[part 1 of 9: packages /SwComponent/AdaptiveApplication to /DataType/Implementation/CPP]
AUTOSAR XML (schema 00049)
package /SwComponent/AdaptiveApplication
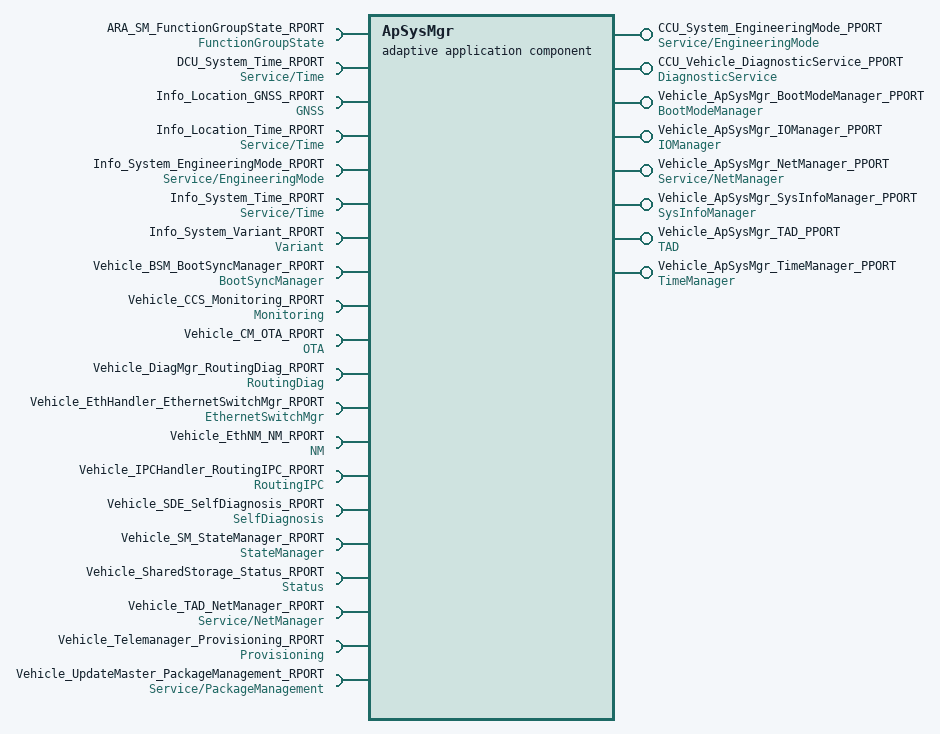
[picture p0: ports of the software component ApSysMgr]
  adaptive application sw component type ApSysMgr
    require port ARA_SM_FunctionGroupState_RPORT: required-interface=FunctionGroupState
    provide port CCU_System_EngineeringMode_PPORT: provided-interface=Service/EngineeringMode
    provide port CCU_Vehicle_DiagnosticService_PPORT: provided-interface=DiagnosticService
    6 x require port:
      DCU_System_Time_RPORT: required-interface=Service/Time
      Info_Location_GNSS_RPORT: required-interface=GNSS
      Info_Location_Time_RPORT: required-interface=Service/Time
      Info_System_EngineeringMode_RPORT: required-interface=Service/EngineeringMode
      Info_System_Time_RPORT: required-interface=Service/Time
      Info_System_Variant_RPORT: required-interface=Variant
    6 x provide port:
      Vehicle_ApSysMgr_BootModeManager_PPORT: provided-interface=BootModeManager
      Vehicle_ApSysMgr_IOManager_PPORT: provided-interface=IOManager
      Vehicle_ApSysMgr_NetManager_PPORT: provided-interface=Service/NetManager
      Vehicle_ApSysMgr_SysInfoManager_PPORT: provided-interface=SysInfoManager
      Vehicle_ApSysMgr_TAD_PPORT: provided-interface=TAD
      Vehicle_ApSysMgr_TimeManager_PPORT: provided-interface=TimeManager
    13 x require port:
      Vehicle_BSM_BootSyncManager_RPORT: required-interface=BootSyncManager
      Vehicle_CCS_Monitoring_RPORT: required-interface=Monitoring
      Vehicle_CM_OTA_RPORT: required-interface=OTA
      Vehicle_DiagMgr_RoutingDiag_RPORT: required-interface=RoutingDiag
      Vehicle_EthHandler_EthernetSwitchMgr_RPORT: required-interface=EthernetSwitchMgr
      Vehicle_EthNM_NM_RPORT: required-interface=NM
      Vehicle_IPCHandler_RoutingIPC_RPORT: required-interface=RoutingIPC
      Vehicle_SDE_SelfDiagnosis_RPORT: required-interface=SelfDiagnosis
      Vehicle_SM_StateManager_RPORT: required-interface=StateManager
      Vehicle_SharedStorage_Status_RPORT: required-interface=Status
      Vehicle_TAD_NetManager_RPORT: required-interface=Service/NetManager
      Vehicle_Telemanager_Provisioning_RPORT: required-interface=Provisioning
      Vehicle_UpdateMaster_PackageManagement_RPORT: required-interface=Service/PackageManagement
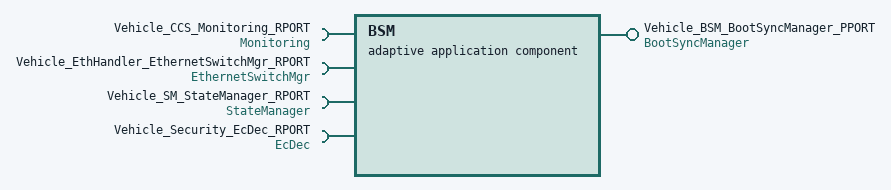
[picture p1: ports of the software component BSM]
  adaptive application sw component type BSM
    provide port Vehicle_BSM_BootSyncManager_PPORT: provided-interface=BootSyncManager
    4 x require port:
      Vehicle_CCS_Monitoring_RPORT: required-interface=Monitoring
      Vehicle_EthHandler_EthernetSwitchMgr_RPORT: required-interface=EthernetSwitchMgr
      Vehicle_SM_StateManager_RPORT: required-interface=StateManager
      Vehicle_Security_EcDec_RPORT: required-interface=EcDec
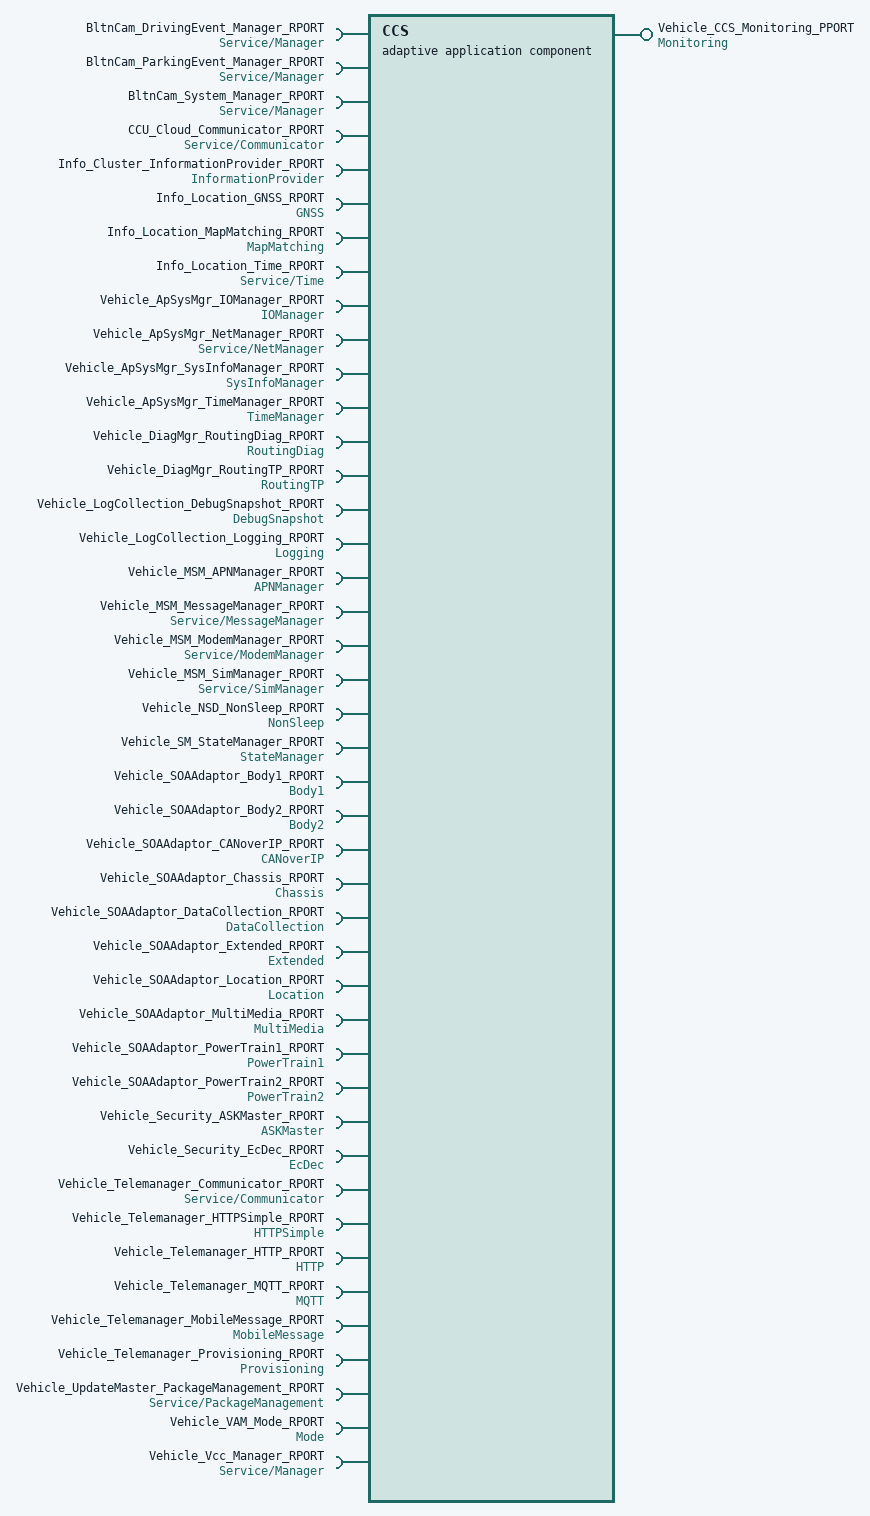
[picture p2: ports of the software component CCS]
  adaptive application sw component type CCS
    12 x require port:
      BltnCam_DrivingEvent_Manager_RPORT: required-interface=Service/Manager
      BltnCam_ParkingEvent_Manager_RPORT: required-interface=Service/Manager
      BltnCam_System_Manager_RPORT: required-interface=Service/Manager
      CCU_Cloud_Communicator_RPORT: required-interface=Service/Communicator
      Info_Cluster_InformationProvider_RPORT: required-interface=InformationProvider
      Info_Location_GNSS_RPORT: required-interface=GNSS
      Info_Location_MapMatching_RPORT: required-interface=MapMatching
      Info_Location_Time_RPORT: required-interface=Service/Time
      Vehicle_ApSysMgr_IOManager_RPORT: required-interface=IOManager
      Vehicle_ApSysMgr_NetManager_RPORT: required-interface=Service/NetManager
      Vehicle_ApSysMgr_SysInfoManager_RPORT: required-interface=SysInfoManager
      Vehicle_ApSysMgr_TimeManager_RPORT: required-interface=TimeManager
    provide port Vehicle_CCS_Monitoring_PPORT: provided-interface=Monitoring
    31 x require port:
      Vehicle_DiagMgr_RoutingDiag_RPORT: required-interface=RoutingDiag
      Vehicle_DiagMgr_RoutingTP_RPORT: required-interface=RoutingTP
      Vehicle_LogCollection_DebugSnapshot_RPORT: required-interface=DebugSnapshot
      Vehicle_LogCollection_Logging_RPORT: required-interface=Logging
      Vehicle_MSM_APNManager_RPORT: required-interface=APNManager
      Vehicle_MSM_MessageManager_RPORT: required-interface=Service/MessageManager
      Vehicle_MSM_ModemManager_RPORT: required-interface=Service/ModemManager
      Vehicle_MSM_SimManager_RPORT: required-interface=Service/SimManager
      Vehicle_NSD_NonSleep_RPORT: required-interface=NonSleep
      Vehicle_SM_StateManager_RPORT: required-interface=StateManager
      Vehicle_SOAAdaptor_Body1_RPORT: required-interface=Body1
      Vehicle_SOAAdaptor_Body2_RPORT: required-interface=Body2
      Vehicle_SOAAdaptor_CANoverIP_RPORT: required-interface=CANoverIP
      Vehicle_SOAAdaptor_Chassis_RPORT: required-interface=Chassis
      Vehicle_SOAAdaptor_DataCollection_RPORT: required-interface=DataCollection
      Vehicle_SOAAdaptor_Extended_RPORT: required-interface=Extended
      Vehicle_SOAAdaptor_Location_RPORT: required-interface=Location
      Vehicle_SOAAdaptor_MultiMedia_RPORT: required-interface=MultiMedia
      Vehicle_SOAAdaptor_PowerTrain1_RPORT: required-interface=PowerTrain1
      Vehicle_SOAAdaptor_PowerTrain2_RPORT: required-interface=PowerTrain2
      Vehicle_Security_ASKMaster_RPORT: required-interface=ASKMaster
      Vehicle_Security_EcDec_RPORT: required-interface=EcDec
      Vehicle_Telemanager_Communicator_RPORT: required-interface=Service/Communicator
      Vehicle_Telemanager_HTTPSimple_RPORT: required-interface=HTTPSimple
      Vehicle_Telemanager_HTTP_RPORT: required-interface=HTTP
      Vehicle_Telemanager_MQTT_RPORT: required-interface=MQTT
      Vehicle_Telemanager_MobileMessage_RPORT: required-interface=MobileMessage
      Vehicle_Telemanager_Provisioning_RPORT: required-interface=Provisioning
      Vehicle_UpdateMaster_PackageManagement_RPORT: required-interface=Service/PackageManagement
      Vehicle_VAM_Mode_RPORT: required-interface=Mode
      Vehicle_Vcc_Manager_RPORT: required-interface=Service/Manager
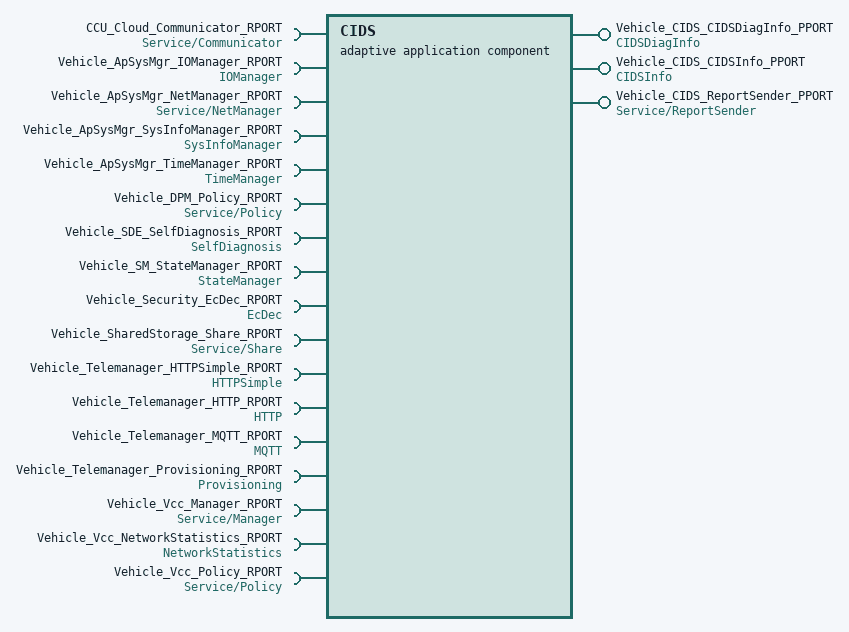
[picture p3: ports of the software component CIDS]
  adaptive application sw component type CIDS
    5 x require port:
      CCU_Cloud_Communicator_RPORT: required-interface=Service/Communicator
      Vehicle_ApSysMgr_IOManager_RPORT: required-interface=IOManager
      Vehicle_ApSysMgr_NetManager_RPORT: required-interface=Service/NetManager
      Vehicle_ApSysMgr_SysInfoManager_RPORT: required-interface=SysInfoManager
      Vehicle_ApSysMgr_TimeManager_RPORT: required-interface=TimeManager
    provide port Vehicle_CIDS_CIDSDiagInfo_PPORT: provided-interface=CIDSDiagInfo
    provide port Vehicle_CIDS_CIDSInfo_PPORT: provided-interface=CIDSInfo
    provide port Vehicle_CIDS_ReportSender_PPORT: provided-interface=Service/ReportSender
    12 x require port:
      Vehicle_DPM_Policy_RPORT: required-interface=Service/Policy
      Vehicle_SDE_SelfDiagnosis_RPORT: required-interface=SelfDiagnosis
      Vehicle_SM_StateManager_RPORT: required-interface=StateManager
      Vehicle_Security_EcDec_RPORT: required-interface=EcDec
      Vehicle_SharedStorage_Share_RPORT: required-interface=Service/Share
      Vehicle_Telemanager_HTTPSimple_RPORT: required-interface=HTTPSimple
      Vehicle_Telemanager_HTTP_RPORT: required-interface=HTTP
      Vehicle_Telemanager_MQTT_RPORT: required-interface=MQTT
      Vehicle_Telemanager_Provisioning_RPORT: required-interface=Provisioning
      Vehicle_Vcc_Manager_RPORT: required-interface=Service/Manager
      Vehicle_Vcc_NetworkStatistics_RPORT: required-interface=NetworkStatistics
      Vehicle_Vcc_Policy_RPORT: required-interface=Service/Policy
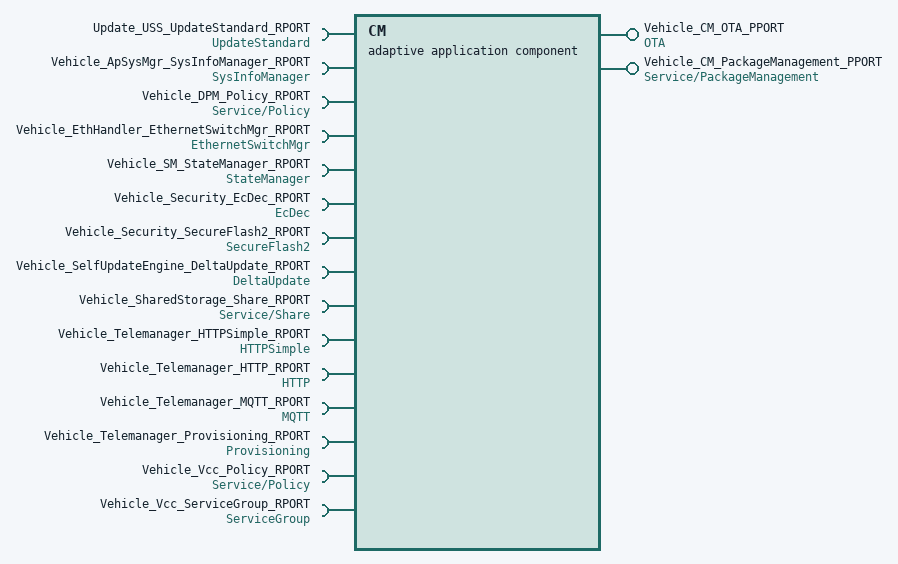
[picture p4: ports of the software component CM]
  adaptive application sw component type CM
    require port Update_USS_UpdateStandard_RPORT: required-interface=UpdateStandard
    require port Vehicle_ApSysMgr_SysInfoManager_RPORT: required-interface=SysInfoManager
    provide port Vehicle_CM_OTA_PPORT: provided-interface=OTA
    provide port Vehicle_CM_PackageManagement_PPORT: provided-interface=Service/PackageManagement
    13 x require port:
      Vehicle_DPM_Policy_RPORT: required-interface=Service/Policy
      Vehicle_EthHandler_EthernetSwitchMgr_RPORT: required-interface=EthernetSwitchMgr
      Vehicle_SM_StateManager_RPORT: required-interface=StateManager
      Vehicle_Security_EcDec_RPORT: required-interface=EcDec
      Vehicle_Security_SecureFlash2_RPORT: required-interface=SecureFlash2
      Vehicle_SelfUpdateEngine_DeltaUpdate_RPORT: required-interface=DeltaUpdate
      Vehicle_SharedStorage_Share_RPORT: required-interface=Service/Share
      Vehicle_Telemanager_HTTPSimple_RPORT: required-interface=HTTPSimple
      Vehicle_Telemanager_HTTP_RPORT: required-interface=HTTP
      Vehicle_Telemanager_MQTT_RPORT: required-interface=MQTT
      Vehicle_Telemanager_Provisioning_RPORT: required-interface=Provisioning
      Vehicle_Vcc_Policy_RPORT: required-interface=Service/Policy
      Vehicle_Vcc_ServiceGroup_RPORT: required-interface=ServiceGroup
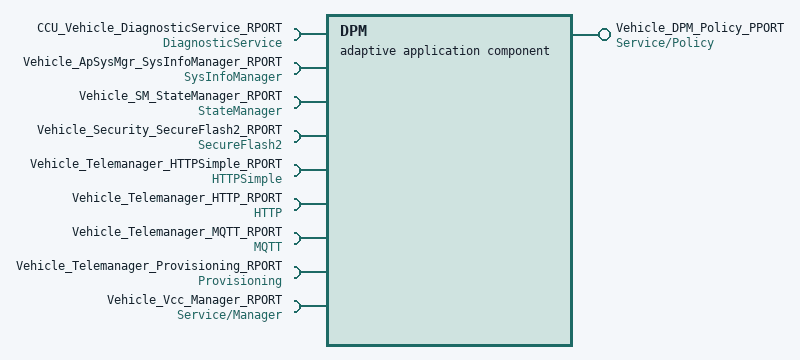
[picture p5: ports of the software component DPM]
  adaptive application sw component type DPM
    require port CCU_Vehicle_DiagnosticService_RPORT: required-interface=DiagnosticService
    require port Vehicle_ApSysMgr_SysInfoManager_RPORT: required-interface=SysInfoManager
    provide port Vehicle_DPM_Policy_PPORT: provided-interface=Service/Policy
    7 x require port:
      Vehicle_SM_StateManager_RPORT: required-interface=StateManager
      Vehicle_Security_SecureFlash2_RPORT: required-interface=SecureFlash2
      Vehicle_Telemanager_HTTPSimple_RPORT: required-interface=HTTPSimple
      Vehicle_Telemanager_HTTP_RPORT: required-interface=HTTP
      Vehicle_Telemanager_MQTT_RPORT: required-interface=MQTT
      Vehicle_Telemanager_Provisioning_RPORT: required-interface=Provisioning
      Vehicle_Vcc_Manager_RPORT: required-interface=Service/Manager
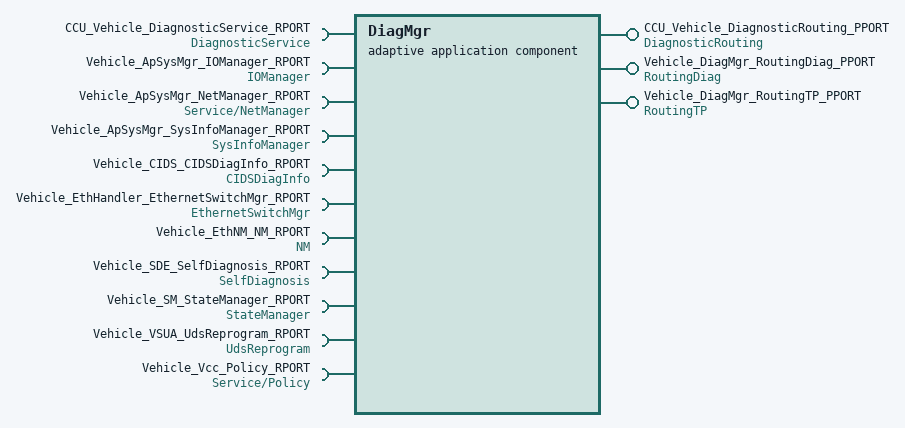
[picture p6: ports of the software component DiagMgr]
  adaptive application sw component type DiagMgr
    provide port CCU_Vehicle_DiagnosticRouting_PPORT: provided-interface=DiagnosticRouting
    5 x require port:
      CCU_Vehicle_DiagnosticService_RPORT: required-interface=DiagnosticService
      Vehicle_ApSysMgr_IOManager_RPORT: required-interface=IOManager
      Vehicle_ApSysMgr_NetManager_RPORT: required-interface=Service/NetManager
      Vehicle_ApSysMgr_SysInfoManager_RPORT: required-interface=SysInfoManager
      Vehicle_CIDS_CIDSDiagInfo_RPORT: required-interface=CIDSDiagInfo
    provide port Vehicle_DiagMgr_RoutingDiag_PPORT: provided-interface=RoutingDiag
    provide port Vehicle_DiagMgr_RoutingTP_PPORT: provided-interface=RoutingTP
    6 x require port:
      Vehicle_EthHandler_EthernetSwitchMgr_RPORT: required-interface=EthernetSwitchMgr
      Vehicle_EthNM_NM_RPORT: required-interface=NM
      Vehicle_SDE_SelfDiagnosis_RPORT: required-interface=SelfDiagnosis
      Vehicle_SM_StateManager_RPORT: required-interface=StateManager
      Vehicle_VSUA_UdsReprogram_RPORT: required-interface=UdsReprogram
      Vehicle_Vcc_Policy_RPORT: required-interface=Service/Policy
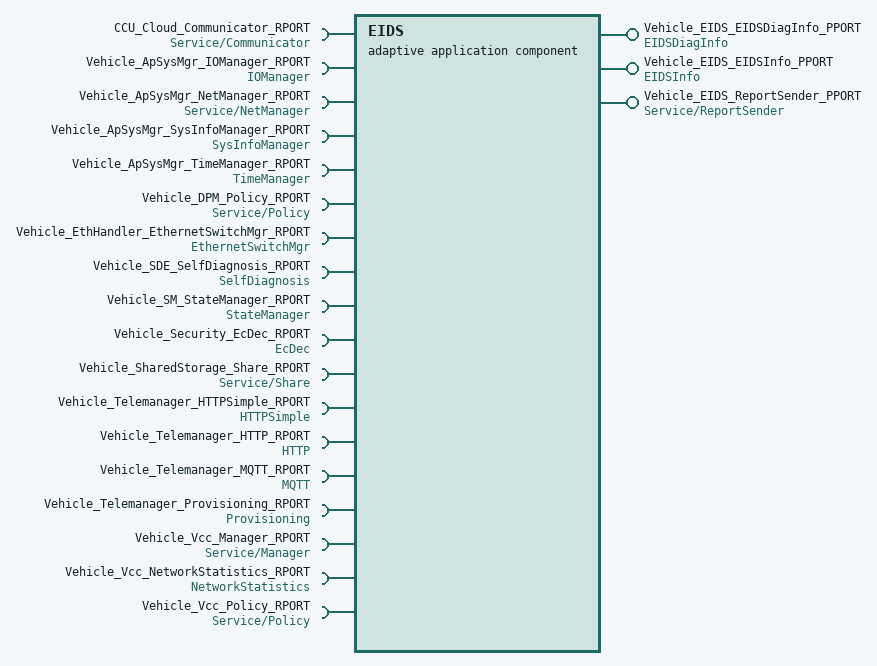
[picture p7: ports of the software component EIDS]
  adaptive application sw component type EIDS
    6 x require port:
      CCU_Cloud_Communicator_RPORT: required-interface=Service/Communicator
      Vehicle_ApSysMgr_IOManager_RPORT: required-interface=IOManager
      Vehicle_ApSysMgr_NetManager_RPORT: required-interface=Service/NetManager
      Vehicle_ApSysMgr_SysInfoManager_RPORT: required-interface=SysInfoManager
      Vehicle_ApSysMgr_TimeManager_RPORT: required-interface=TimeManager
      Vehicle_DPM_Policy_RPORT: required-interface=Service/Policy
    provide port Vehicle_EIDS_EIDSDiagInfo_PPORT: provided-interface=EIDSDiagInfo
    provide port Vehicle_EIDS_EIDSInfo_PPORT: provided-interface=EIDSInfo
    provide port Vehicle_EIDS_ReportSender_PPORT: provided-interface=Service/ReportSender
    12 x require port:
      Vehicle_EthHandler_EthernetSwitchMgr_RPORT: required-interface=EthernetSwitchMgr
      Vehicle_SDE_SelfDiagnosis_RPORT: required-interface=SelfDiagnosis
      Vehicle_SM_StateManager_RPORT: required-interface=StateManager
      Vehicle_Security_EcDec_RPORT: required-interface=EcDec
      Vehicle_SharedStorage_Share_RPORT: required-interface=Service/Share
      Vehicle_Telemanager_HTTPSimple_RPORT: required-interface=HTTPSimple
      Vehicle_Telemanager_HTTP_RPORT: required-interface=HTTP
      Vehicle_Telemanager_MQTT_RPORT: required-interface=MQTT
      Vehicle_Telemanager_Provisioning_RPORT: required-interface=Provisioning
      Vehicle_Vcc_Manager_RPORT: required-interface=Service/Manager
      Vehicle_Vcc_NetworkStatistics_RPORT: required-interface=NetworkStatistics
      Vehicle_Vcc_Policy_RPORT: required-interface=Service/Policy
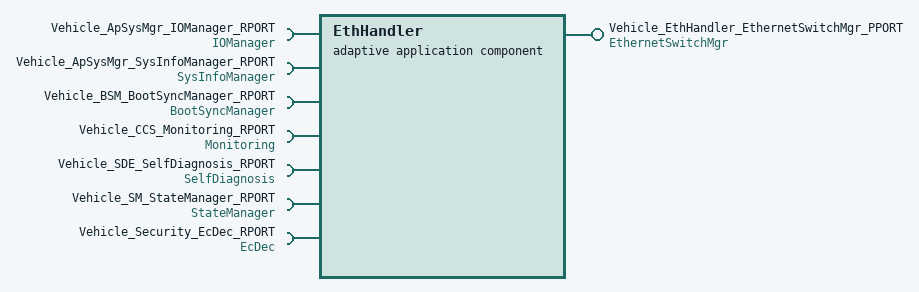
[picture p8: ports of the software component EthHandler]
  adaptive application sw component type EthHandler
    4 x require port:
      Vehicle_ApSysMgr_IOManager_RPORT: required-interface=IOManager
      Vehicle_ApSysMgr_SysInfoManager_RPORT: required-interface=SysInfoManager
      Vehicle_BSM_BootSyncManager_RPORT: required-interface=BootSyncManager
      Vehicle_CCS_Monitoring_RPORT: required-interface=Monitoring
    provide port Vehicle_EthHandler_EthernetSwitchMgr_PPORT: provided-interface=EthernetSwitchMgr
    require port Vehicle_SDE_SelfDiagnosis_RPORT: required-interface=SelfDiagnosis
    require port Vehicle_SM_StateManager_RPORT: required-interface=StateManager
    require port Vehicle_Security_EcDec_RPORT: required-interface=EcDec
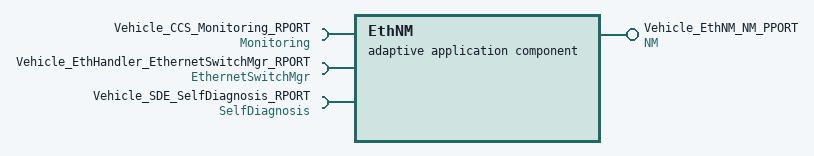
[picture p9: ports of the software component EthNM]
  adaptive application sw component type EthNM
    require port Vehicle_CCS_Monitoring_RPORT: required-interface=Monitoring
    require port Vehicle_EthHandler_EthernetSwitchMgr_RPORT: required-interface=EthernetSwitchMgr
    provide port Vehicle_EthNM_NM_PPORT: provided-interface=NM
    require port Vehicle_SDE_SelfDiagnosis_RPORT: required-interface=SelfDiagnosis
  adaptive application sw component type FlashingAdaptor
    5 x require port:
      Info_Update_RFSManager_RPORT: required-interface=RFSManager
      Vehicle_ApSysMgr_IOManager_RPORT: required-interface=IOManager
      Vehicle_ApSysMgr_NetManager_RPORT: required-interface=Service/NetManager
      Vehicle_ApSysMgr_SysInfoManager_RPORT: required-interface=SysInfoManager
      Vehicle_DiagMgr_RoutingDiag_RPORT: required-interface=RoutingDiag
    provide port Vehicle_FlashingAdaptor_PackageManagement_PPORT: provided-interface=Service/PackageManagement
    4 x require port:
      Vehicle_RFSM_RemoteFileSystemManager_RPORT: required-interface=RemoteFileSystemManager
      Vehicle_SM_StateManager_RPORT: required-interface=StateManager
      Vehicle_Security_ASKMaster_RPORT: required-interface=ASKMaster
      Vehicle_Security_OEUK_RPORT: required-interface=OEUK
  adaptive application sw component type FoDClient
    require port Vehicle_ApSysMgr_SysInfoManager_RPORT: required-interface=SysInfoManager
    require port Vehicle_ApSysMgr_TimeManager_RPORT: required-interface=TimeManager
    provide port Vehicle_FoDClient_ActivationManager_PPORT: provided-interface=ActivationManager
    require port Vehicle_FoDMaster_Support_RPORT: required-interface=Support
    require port Vehicle_Security_EcDec_RPORT: required-interface=EcDec
  adaptive application sw component type FoDMaster
    provide port CCU_FoD_Screen_PPORT: provided-interface=Service/Screen
    5 x require port:
      CCU_Vehicle_DiagnosticService_RPORT: required-interface=DiagnosticService
      Vehicle_ApSysMgr_IOManager_RPORT: required-interface=IOManager
      Vehicle_ApSysMgr_NetManager_RPORT: required-interface=Service/NetManager
      Vehicle_ApSysMgr_SysInfoManager_RPORT: required-interface=SysInfoManager
      Vehicle_DiagMgr_RoutingDiag_RPORT: required-interface=RoutingDiag
    provide port Vehicle_FoDMaster_Support_PPORT: provided-interface=Support
    11 x require port:
      Vehicle_SM_StateManager_RPORT: required-interface=StateManager
      Vehicle_SOAAdaptor_Body1_RPORT: required-interface=Body1
      Vehicle_SOAAdaptor_CANoverIP_RPORT: required-interface=CANoverIP
      Vehicle_SOAAdaptor_Extended_RPORT: required-interface=Extended
      Vehicle_SOAAdaptor_MultiMedia_RPORT: required-interface=MultiMedia
      Vehicle_Security_ASKMaster_RPORT: required-interface=ASKMaster
      Vehicle_Telemanager_HTTP_RPORT: required-interface=HTTP
      Vehicle_Telemanager_Provisioning_RPORT: required-interface=Provisioning
      Vehicle_UpdateMaster_PackageManagement_RPORT: required-interface=Service/PackageManagement
      Vehicle_VSM_SafeStatusManagement_RPORT: required-interface=SafeStatusManagement
      Vehicle_Vcc_Manager_RPORT: required-interface=Service/Manager
  adaptive application sw component type IPCHandler
    4 x require port:
      Vehicle_ApSysMgr_BootModeManager_RPORT: required-interface=BootModeManager
      Vehicle_ApSysMgr_NetManager_RPORT: required-interface=Service/NetManager
      Vehicle_ApSysMgr_SysInfoManager_RPORT: required-interface=SysInfoManager
      Vehicle_CCS_Monitoring_RPORT: required-interface=Monitoring
    provide port Vehicle_IPCHandler_RoutingIPC_PPORT: provided-interface=RoutingIPC
    require port Vehicle_LogCollection_DebugSnapshot_RPORT: required-interface=DebugSnapshot
    require port Vehicle_LogCollection_Logging_RPORT: required-interface=Logging
    require port Vehicle_SM_StateManager_RPORT: required-interface=StateManager
  adaptive application sw component type LogCollection
    require port Vehicle_CCS_Monitoring_RPORT: required-interface=Monitoring
    provide port Vehicle_LogCollection_DebugSnapshot_PPORT: provided-interface=DebugSnapshot
    provide port Vehicle_LogCollection_Logging_PPORT: provided-interface=Logging
    require port Vehicle_SDE_SelfDiagnosis_RPORT: required-interface=SelfDiagnosis
    require port Vehicle_Security_EcDec_RPORT: required-interface=EcDec
    require port Vehicle_SharedStorage_Share_RPORT: required-interface=Service/Share
  adaptive application sw component type MSM
    18 x require port:
      DCU_System_PowerManagement_RPORT: required-interface=PowerManagement
      DCU_Telephony_ConnectionContext_{1..3}_RPORT: required-interface=ConnectionContext
      DCU_Telephony_ConnectionContext_RPORT: required-interface=ConnectionContext
      DCU_Telephony_ConnectionManager_RPORT: required-interface=ConnectionManager
      DCU_Telephony_EngineeringMode_RPORT: required-interface=Service/EngineeringMode
      DCU_Telephony_MessageManager_RPORT: required-interface=Service/MessageManager
      DCU_Telephony_ModemManager_RPORT: required-interface=Service/ModemManager
      DCU_Telephony_NetworkInformation_RPORT: required-interface=NetworkInformation
      DCU_Telephony_SimManager_RPORT: required-interface=Service/SimManager
      DCU_Telephony_VoiceCallManager_RPORT: required-interface=VoiceCallManager
      Vehicle_ApSysMgr_IOManager_RPORT: required-interface=IOManager
      Vehicle_ApSysMgr_NetManager_RPORT: required-interface=Service/NetManager
      Vehicle_ApSysMgr_SysInfoManager_RPORT: required-interface=SysInfoManager
      Vehicle_CCS_Monitoring_RPORT: required-interface=Monitoring
      Vehicle_LogCollection_DebugSnapshot_RPORT: required-interface=DebugSnapshot
      Vehicle_LogCollection_Logging_RPORT: required-interface=Logging
    5 x provide port:
      Vehicle_MSM_APNManager_PPORT: provided-interface=APNManager
      Vehicle_MSM_MessageManager_PPORT: provided-interface=Service/MessageManager
      Vehicle_MSM_ModemManager_PPORT: provided-interface=Service/ModemManager
      Vehicle_MSM_NetworkManager_PPORT: provided-interface=NetworkManager
      Vehicle_MSM_SimManager_PPORT: provided-interface=Service/SimManager
    4 x require port:
      Vehicle_SM_StateManager_RPORT: required-interface=StateManager
      Vehicle_Telemanager_Provisioning_RPORT: required-interface=Provisioning
      Vehicle_UpdateMaster_PackageManagement_RPORT: required-interface=Service/PackageManagement
      Vehicle_Vcc_Manager_RPORT: required-interface=Service/Manager
  adaptive application sw component type NSD
    8 x require port:
      Vehicle_ApSysMgr_IOManager_RPORT: required-interface=IOManager
      Vehicle_ApSysMgr_NetManager_RPORT: required-interface=Service/NetManager
      Vehicle_ApSysMgr_TimeManager_RPORT: required-interface=TimeManager
      Vehicle_CCS_Monitoring_RPORT: required-interface=Monitoring
      Vehicle_DiagMgr_RoutingDiag_RPORT: required-interface=RoutingDiag
      Vehicle_IPCHandler_RoutingIPC_RPORT: required-interface=RoutingIPC
      Vehicle_LogCollection_DebugSnapshot_RPORT: required-interface=DebugSnapshot
      Vehicle_LogCollection_Logging_RPORT: required-interface=Logging
    provide port Vehicle_NSD_NonSleep_PPORT: provided-interface=NonSleep
    require port Vehicle_SM_StateManager_RPORT: required-interface=StateManager
    require port Vehicle_SOAAdaptor_Body1_RPORT: required-interface=Body1
  adaptive application sw component type OtaClient
    31 x require port:
      CCU_Cloud_Communicator_RPORT: required-interface=Service/Communicator
      Info_Setup_GeneralSettings_RPORT: required-interface=GeneralSettings
      Info_Update_InteractionManager_RPORT: required-interface=InteractionManager
      Info_Update_RFSManager_RPORT: required-interface=RFSManager
      Vehicle_ApSysMgr_IOManager_RPORT: required-interface=IOManager
      Vehicle_ApSysMgr_NetManager_RPORT: required-interface=Service/NetManager
      Vehicle_ApSysMgr_SysInfoManager_RPORT: required-interface=SysInfoManager
      Vehicle_ApSysMgr_TimeManager_RPORT: required-interface=TimeManager
      Vehicle_DiagMgr_RoutingDiag_RPORT: required-interface=RoutingDiag
      Vehicle_LogCollection_DebugSnapshot_RPORT: required-interface=DebugSnapshot
      Vehicle_LogCollection_Logging_RPORT: required-interface=Logging
      Vehicle_RFSM_RemoteFileSystemManager_RPORT: required-interface=RemoteFileSystemManager
      Vehicle_SDE_SelfDiagnosis_RPORT: required-interface=SelfDiagnosis
      Vehicle_SM_StateManager_RPORT: required-interface=StateManager
      Vehicle_SOAAdaptor_Body1_RPORT: required-interface=Body1
      Vehicle_SOAAdaptor_Body2_RPORT: required-interface=Body2
      Vehicle_SOAAdaptor_CANoverIP_RPORT: required-interface=CANoverIP
      Vehicle_SOAAdaptor_Chassis_RPORT: required-interface=Chassis
      Vehicle_SOAAdaptor_Extended_RPORT: required-interface=Extended
      Vehicle_SOAAdaptor_Location_RPORT: required-interface=Location
      Vehicle_SOAAdaptor_MultiMedia_RPORT: required-interface=MultiMedia
      Vehicle_SOAAdaptor_PowerTrain1_RPORT: required-interface=PowerTrain1
      Vehicle_SOAAdaptor_PowerTrain2_RPORT: required-interface=PowerTrain2
      Vehicle_Telemanager_Communicator_RPORT: required-interface=Service/Communicator
      Vehicle_Telemanager_HTTPSimple_RPORT: required-interface=HTTPSimple
      Vehicle_Telemanager_HTTP_RPORT: required-interface=HTTP
      Vehicle_Telemanager_MQTT_RPORT: required-interface=MQTT
      Vehicle_Telemanager_Provisioning_RPORT: required-interface=Provisioning
      Vehicle_TraceEngine_Log_RPORT: required-interface=Log
      Vehicle_UpdateMaster_PackageManagement_RPORT: required-interface=Service/PackageManagement
      Vehicle_Vcc_Manager_RPORT: required-interface=Service/Manager
  adaptive application sw component type PHM
    require port Vehicle_CCS_Monitoring_RPORT: required-interface=Monitoring
    require port Vehicle_IPCHandler_RoutingIPC_RPORT: required-interface=RoutingIPC
  adaptive application sw component type RFSM
    require port Info_Update_RFSManager_RPORT: required-interface=RFSManager
    require port Vehicle_CCS_Monitoring_RPORT: required-interface=Monitoring
    provide port Vehicle_RFSM_RemoteFileSystemManager_PPORT: provided-interface=RemoteFileSystemManager
  adaptive application sw component type RTA
    provide port CCU_Mode_Routines_PPORT: provided-interface=Routines
    10 x require port:
      Vehicle_ApSysMgr_IOManager_RPORT: required-interface=IOManager
      Vehicle_SOAAdaptor_Body1_RPORT: required-interface=Body1
      Vehicle_SOAAdaptor_Body2_RPORT: required-interface=Body2
      Vehicle_SOAAdaptor_CANoverIP_RPORT: required-interface=CANoverIP
      Vehicle_SOAAdaptor_Chassis_RPORT: required-interface=Chassis
      Vehicle_SOAAdaptor_Extended_RPORT: required-interface=Extended
      Vehicle_SOAAdaptor_MultiMedia_RPORT: required-interface=MultiMedia
      Vehicle_SOAAdaptor_PowerTrain1_RPORT: required-interface=PowerTrain1
      Vehicle_SOAAdaptor_PowerTrain2_RPORT: required-interface=PowerTrain2
      Vehicle_VAS_VehicleAPI_RPORT: required-interface=VehicleAPI
  adaptive application sw component type SDE
    require port ARA_UCM_PackageManagement_RPORT: required-interface=Service/PackageManagement
    provide port Update_USS_UpdateStandard_PPORT: provided-interface=UpdateStandard
    15 x require port:
      Vehicle_ApSysMgr_IOManager_RPORT: required-interface=IOManager
      Vehicle_ApSysMgr_NetManager_RPORT: required-interface=Service/NetManager
      Vehicle_ApSysMgr_SysInfoManager_RPORT: required-interface=SysInfoManager
      Vehicle_BSM_BootSyncManager_RPORT: required-interface=BootSyncManager
      Vehicle_CCS_Monitoring_RPORT: required-interface=Monitoring
      Vehicle_CIDS_CIDSDiagInfo_RPORT: required-interface=CIDSDiagInfo
      Vehicle_CM_PackageManagement_RPORT: required-interface=Service/PackageManagement
      Vehicle_DiagMgr_RoutingDiag_RPORT: required-interface=RoutingDiag
      Vehicle_EIDS_EIDSDiagInfo_RPORT: required-interface=EIDSDiagInfo
      Vehicle_EthHandler_EthernetSwitchMgr_RPORT: required-interface=EthernetSwitchMgr
      Vehicle_EthNM_NM_RPORT: required-interface=NM
      Vehicle_FoDClient_ActivationManager_RPORT: required-interface=ActivationManager
      Vehicle_FoDMaster_Support_RPORT: required-interface=Support
      Vehicle_LogCollection_Logging_RPORT: required-interface=Logging
      Vehicle_NSD_NonSleep_RPORT: required-interface=NonSleep
    provide port Vehicle_SDE_SelfDiagnosis_PPORT: provided-interface=SelfDiagnosis
    8 x require port:
      Vehicle_Security_EcDec_RPORT: required-interface=EcDec
      Vehicle_Security_IVPA_RPORT: required-interface=IVPA
      Vehicle_Security_MassProc_RPORT: required-interface=MassProc
      Vehicle_SharedStorage_Share_RPORT: required-interface=Service/Share
      Vehicle_SharedStorage_Status_RPORT: required-interface=Status
      Vehicle_UpdateMaster_PackageManagement_RPORT: required-interface=Service/PackageManagement
      Vehicle_VSUA_UdsReprogram_RPORT: required-interface=UdsReprogram
      Vehicle_Vcc_Policy_RPORT: required-interface=Service/Policy
  adaptive application sw component type SM
    provide port ARA_SM_FunctionGroupState_PPORT: provided-interface=FunctionGroupState
    provide port ARA_SM_UpdateRequest_PPORT: provided-interface=UpdateRequest
    5 x require port:
      Vehicle_ApSysMgr_IOManager_RPORT: required-interface=IOManager
      Vehicle_ApSysMgr_NetManager_RPORT: required-interface=Service/NetManager
      Vehicle_CCS_Monitoring_RPORT: required-interface=Monitoring
      Vehicle_IPCHandler_RoutingIPC_RPORT: required-interface=RoutingIPC
      Vehicle_MSM_MessageManager_RPORT: required-interface=Service/MessageManager
    provide port Vehicle_SM_StateManager_PPORT: provided-interface=StateManager
    require port Vehicle_Telemanager_MobileMessage_RPORT: required-interface=MobileMessage
    require port Vehicle_UpdateMaster_PackageManagement_RPORT: required-interface=Service/PackageManagement
  adaptive application sw component type SOAAdaptor
    provide port CCU_Vehicle_S2S_PPORT: provided-interface=S2S
    6 x require port:
      DCU_System_Variation_RPORT: required-interface=Variation
      Vehicle_ApSysMgr_NetManager_RPORT: required-interface=Service/NetManager
      Vehicle_ApSysMgr_TimeManager_RPORT: required-interface=TimeManager
      Vehicle_CCS_Monitoring_RPORT: required-interface=Monitoring
      Vehicle_SDE_SelfDiagnosis_RPORT: required-interface=SelfDiagnosis
      Vehicle_SM_StateManager_RPORT: required-interface=StateManager
    11 x provide port:
      Vehicle_SOAAdaptor_Body1_PPORT: provided-interface=Body1
      Vehicle_SOAAdaptor_Body2_PPORT: provided-interface=Body2
      Vehicle_SOAAdaptor_CANoverIP_PPORT: provided-interface=CANoverIP
      Vehicle_SOAAdaptor_Chassis_PPORT: provided-interface=Chassis
      Vehicle_SOAAdaptor_DataCollection_PPORT: provided-interface=DataCollection
      Vehicle_SOAAdaptor_DynamicRouting_PPORT: provided-interface=DynamicRouting
      Vehicle_SOAAdaptor_Extended_PPORT: provided-interface=Extended
      Vehicle_SOAAdaptor_Location_PPORT: provided-interface=Location
      Vehicle_SOAAdaptor_MultiMedia_PPORT: provided-interface=MultiMedia
      Vehicle_SOAAdaptor_PowerTrain1_PPORT: provided-interface=PowerTrain1
      Vehicle_SOAAdaptor_PowerTrain2_PPORT: provided-interface=PowerTrain2
    require port Vehicle_TAD_NetManager_RPORT: required-interface=Service/NetManager
  adaptive application sw component type Security
    require port Vehicle_DiagMgr_RoutingDiag_RPORT: required-interface=RoutingDiag
    require port Vehicle_IPCHandler_RoutingIPC_RPORT: required-interface=RoutingIPC
    6 x provide port:
      Vehicle_Security_ASKMaster_PPORT: provided-interface=ASKMaster
      Vehicle_Security_EcDec_PPORT: provided-interface=EcDec
      Vehicle_Security_IVPA_PPORT: provided-interface=IVPA
      Vehicle_Security_MassProc_PPORT: provided-interface=MassProc
      Vehicle_Security_OEUK_PPORT: provided-interface=OEUK
      Vehicle_Security_SecureFlash2_PPORT: provided-interface=SecureFlash2
  adaptive application sw component type SelfUpdateEngine
    8 x require port:
      ARA_UCM_PackageManagement_RPORT: required-interface=Service/PackageManagement
      Vehicle_ApSysMgr_SysInfoManager_RPORT: required-interface=SysInfoManager
      Vehicle_BSM_BootSyncManager_RPORT: required-interface=BootSyncManager
      Vehicle_CM_OTA_RPORT: required-interface=OTA
      Vehicle_EthHandler_EthernetSwitchMgr_RPORT: required-interface=EthernetSwitchMgr
      Vehicle_IPCHandler_RoutingIPC_RPORT: required-interface=RoutingIPC
      Vehicle_SM_StateManager_RPORT: required-interface=StateManager
      Vehicle_Security_SecureFlash2_RPORT: required-interface=SecureFlash2
    provide port Vehicle_SelfUpdateEngine_DeltaUpdate_PPORT: provided-interface=DeltaUpdate
  adaptive application sw component type SharedStorage
    provide port CCU_SharedStorage_Share_PPORT: provided-interface=Service/Share
    7 x require port:
      Vehicle_ApSysMgr_IOManager_RPORT: required-interface=IOManager
      Vehicle_ApSysMgr_NetManager_RPORT: required-interface=Service/NetManager
      Vehicle_ApSysMgr_SysInfoManager_RPORT: required-interface=SysInfoManager
      Vehicle_DPM_Policy_RPORT: required-interface=Service/Policy
      Vehicle_SM_StateManager_RPORT: required-interface=StateManager
      Vehicle_Security_SecureFlash2_RPORT: required-interface=SecureFlash2
      Vehicle_SelfUpdateEngine_DeltaUpdate_RPORT: required-interface=DeltaUpdate
    provide port Vehicle_SharedStorage_Share_PPORT: provided-interface=Service/Share
    provide port Vehicle_SharedStorage_Status_PPORT: provided-interface=Status
    require port Vehicle_Telemanager_Provisioning_RPORT: required-interface=Provisioning
    require port Vehicle_Vcc_Policy_RPORT: required-interface=Service/Policy
  adaptive application sw component type TAD
    10 x require port:
      Info_Cloud_ProvisioningTable_RPORT: required-interface=Service/ProvisioningTable
      Vehicle_ApSysMgr_IOManager_RPORT: required-interface=IOManager
      Vehicle_ApSysMgr_NetManager_RPORT: required-interface=Service/NetManager
      Vehicle_ApSysMgr_SysInfoManager_RPORT: required-interface=SysInfoManager
      Vehicle_ApSysMgr_TAD_RPORT: required-interface=TAD
      Vehicle_EthHandler_EthernetSwitchMgr_RPORT: required-interface=EthernetSwitchMgr
      Vehicle_EthNM_NM_RPORT: required-interface=NM
      Vehicle_IPCHandler_RoutingIPC_RPORT: required-interface=RoutingIPC
      Vehicle_SM_StateManager_RPORT: required-interface=StateManager
      Vehicle_SOAAdaptor_CANoverIP_RPORT: required-interface=CANoverIP
    provide port Vehicle_TAD_NetManager_PPORT: provided-interface=Service/NetManager
    6 x require port:
      Vehicle_Telemanager_Communicator_RPORT: required-interface=Service/Communicator
      Vehicle_Telemanager_MQTT_RPORT: required-interface=MQTT
      Vehicle_Telemanager_Provisioning_RPORT: required-interface=Provisioning
      Vehicle_UpdateMaster_PackageManagement_RPORT: required-interface=Service/PackageManagement
      Vehicle_VSM_SafeStatusManagement_RPORT: required-interface=SafeStatusManagement
      Vehicle_Vcc_Policy_RPORT: required-interface=Service/Policy
  adaptive application sw component type Telemanager
    provide port CCU_Cloud_Communicator_PPORT: provided-interface=Service/Communicator
    provide port CCU_Cloud_ProvisioningTable_PPORT: provided-interface=Service/ProvisioningTable
    24 x require port:
      CCU_Vehicle_DiagnosticService_RPORT: required-interface=DiagnosticService
      Info_Cloud_EngineeringMode_RPORT: required-interface=Service/EngineeringMode
      Info_Cloud_ProvisioningTable_RPORT: required-interface=Service/ProvisioningTable
      Info_Location_GNSS_RPORT: required-interface=GNSS
      Info_Location_MapMatching_RPORT: required-interface=MapMatching
      Info_Location_Time_RPORT: required-interface=Service/Time
      Vehicle_ApSysMgr_IOManager_RPORT: required-interface=IOManager
      Vehicle_ApSysMgr_NetManager_RPORT: required-interface=Service/NetManager
      Vehicle_ApSysMgr_SysInfoManager_RPORT: required-interface=SysInfoManager
      Vehicle_ApSysMgr_TimeManager_RPORT: required-interface=TimeManager
      Vehicle_CCS_Monitoring_RPORT: required-interface=Monitoring
      Vehicle_CIDS_CIDSInfo_RPORT: required-interface=CIDSInfo
      Vehicle_CIDS_ReportSender_RPORT: required-interface=Service/ReportSender
      Vehicle_EIDS_EIDSInfo_RPORT: required-interface=EIDSInfo
      Vehicle_EIDS_ReportSender_RPORT: required-interface=Service/ReportSender
      Vehicle_LogCollection_DebugSnapshot_RPORT: required-interface=DebugSnapshot
      Vehicle_LogCollection_Logging_RPORT: required-interface=Logging
      Vehicle_MSM_APNManager_RPORT: required-interface=APNManager
      Vehicle_MSM_MessageManager_RPORT: required-interface=Service/MessageManager
      Vehicle_MSM_ModemManager_RPORT: required-interface=Service/ModemManager
      Vehicle_MSM_NetworkManager_RPORT: required-interface=NetworkManager
      Vehicle_MSM_SimManager_RPORT: required-interface=Service/SimManager
      Vehicle_SM_StateManager_RPORT: required-interface=StateManager
      Vehicle_SOAAdaptor_MultiMedia_RPORT: required-interface=MultiMedia
    6 x provide port:
      Vehicle_Telemanager_Communicator_PPORT: provided-interface=Service/Communicator
      Vehicle_Telemanager_HTTPSimple_PPORT: provided-interface=HTTPSimple
      Vehicle_Telemanager_HTTP_PPORT: provided-interface=HTTP
      Vehicle_Telemanager_MQTT_PPORT: provided-interface=MQTT
      Vehicle_Telemanager_MobileMessage_PPORT: provided-interface=MobileMessage
      Vehicle_Telemanager_Provisioning_PPORT: provided-interface=Provisioning
    require port Vehicle_Vcc_Manager_RPORT: required-interface=Service/Manager
  adaptive application sw component type TraceEngine
    6 x require port:
      Info_System_EngineeringMode_RPORT: required-interface=Service/EngineeringMode
      Vehicle_ApSysMgr_IOManager_RPORT: required-interface=IOManager
      Vehicle_CCS_Monitoring_RPORT: required-interface=Monitoring
      Vehicle_DPM_Policy_RPORT: required-interface=Service/Policy
      Vehicle_EthHandler_EthernetSwitchMgr_RPORT: required-interface=EthernetSwitchMgr
      Vehicle_SM_StateManager_RPORT: required-interface=StateManager
    provide port Vehicle_TraceEngine_Log_PPORT: provided-interface=Log
  adaptive application sw component type UCM
    require port ARA_SM_UpdateRequest_RPORT: required-interface=UpdateRequest
    provide port ARA_UCM_PackageManagement_PPORT: provided-interface=Service/PackageManagement
    8 x require port:
      Update_USS_UpdateStandard_RPORT: required-interface=UpdateStandard
      Vehicle_ApSysMgr_SysInfoManager_RPORT: required-interface=SysInfoManager
      Vehicle_IPCHandler_RoutingIPC_RPORT: required-interface=RoutingIPC
      Vehicle_SM_StateManager_RPORT: required-interface=StateManager
      Vehicle_Security_EcDec_RPORT: required-interface=EcDec
      Vehicle_Security_OEUK_RPORT: required-interface=OEUK
      Vehicle_Security_SecureFlash2_RPORT: required-interface=SecureFlash2
      Vehicle_SelfUpdateEngine_DeltaUpdate_RPORT: required-interface=DeltaUpdate
  adaptive application sw component type UMT
    7 x require port:
      Vehicle_SOAAdaptor_Body1_RPORT: required-interface=Body1
      Vehicle_SOAAdaptor_CANoverIP_RPORT: required-interface=CANoverIP
      Vehicle_SOAAdaptor_Chassis_RPORT: required-interface=Chassis
      Vehicle_SOAAdaptor_Extended_RPORT: required-interface=Extended
      Vehicle_SOAAdaptor_MultiMedia_RPORT: required-interface=MultiMedia
      Vehicle_SOAAdaptor_PowerTrain1_RPORT: required-interface=PowerTrain1
      Vehicle_SOAAdaptor_PowerTrain2_RPORT: required-interface=PowerTrain2
  adaptive application sw component type UpdateMaster
    require port ARA_UCM_PackageManagement_RPORT: required-interface=Service/PackageManagement
    provide port CCU_Update_Screen_PPORT: provided-interface=Service/Screen
    29 x require port:
      CCU_Vehicle_DiagnosticService_RPORT: required-interface=DiagnosticService
      Info_Setup_GeneralSettings_RPORT: required-interface=GeneralSettings
      Info_Update_InteractionManager_RPORT: required-interface=InteractionManager
      Update_USS_UpdateStandard_RPORT: required-interface=UpdateStandard
      Vehicle_ApSysMgr_IOManager_RPORT: required-interface=IOManager
      Vehicle_ApSysMgr_NetManager_RPORT: required-interface=Service/NetManager
      Vehicle_ApSysMgr_SysInfoManager_RPORT: required-interface=SysInfoManager
      Vehicle_ApSysMgr_TimeManager_RPORT: required-interface=TimeManager
      Vehicle_CM_PackageManagement_RPORT: required-interface=Service/PackageManagement
      Vehicle_DiagMgr_RoutingDiag_RPORT: required-interface=RoutingDiag
      Vehicle_FlashingAdaptor_PackageManagement_RPORT: required-interface=Service/PackageManagement
      Vehicle_IPCHandler_RoutingIPC_RPORT: required-interface=RoutingIPC
      Vehicle_LogCollection_DebugSnapshot_RPORT: required-interface=DebugSnapshot
      Vehicle_LogCollection_Logging_RPORT: required-interface=Logging
      Vehicle_SDE_SelfDiagnosis_RPORT: required-interface=SelfDiagnosis
      Vehicle_SM_StateManager_RPORT: required-interface=StateManager
      Vehicle_SOAAdaptor_Body1_RPORT: required-interface=Body1
      Vehicle_SOAAdaptor_Body2_RPORT: required-interface=Body2
      Vehicle_SOAAdaptor_CANoverIP_RPORT: required-interface=CANoverIP
      Vehicle_SOAAdaptor_Chassis_RPORT: required-interface=Chassis
      Vehicle_SOAAdaptor_Extended_RPORT: required-interface=Extended
      Vehicle_SOAAdaptor_Location_RPORT: required-interface=Location
      Vehicle_SOAAdaptor_MultiMedia_RPORT: required-interface=MultiMedia
      Vehicle_SOAAdaptor_PowerTrain1_RPORT: required-interface=PowerTrain1
      Vehicle_SOAAdaptor_PowerTrain2_RPORT: required-interface=PowerTrain2
      Vehicle_Security_ASKMaster_RPORT: required-interface=ASKMaster
      Vehicle_Security_OEUK_RPORT: required-interface=OEUK
      Vehicle_Telemanager_Provisioning_RPORT: required-interface=Provisioning
      Vehicle_TraceEngine_Log_RPORT: required-interface=Log
    provide port Vehicle_UpdateMaster_PackageManagement_PPORT: provided-interface=Service/PackageManagement
    require port Vehicle_VSM_SafeStatusManagement_RPORT: required-interface=SafeStatusManagement
  adaptive application sw component type VAM
    34 x require port:
      CCU_Cloud_Communicator_RPORT: required-interface=Service/Communicator
      Info_Location_GNSS_RPORT: required-interface=GNSS
      Info_Location_MapMatching_RPORT: required-interface=MapMatching
      Info_Location_Time_RPORT: required-interface=Service/Time
      Vehicle_ApSysMgr_IOManager_RPORT: required-interface=IOManager
      Vehicle_ApSysMgr_NetManager_RPORT: required-interface=Service/NetManager
      Vehicle_ApSysMgr_SysInfoManager_RPORT: required-interface=SysInfoManager
      Vehicle_CCS_Monitoring_RPORT: required-interface=Monitoring
      Vehicle_DPM_Policy_RPORT: required-interface=Service/Policy
      Vehicle_DiagMgr_RoutingDiag_RPORT: required-interface=RoutingDiag
      Vehicle_MSM_APNManager_RPORT: required-interface=APNManager
      Vehicle_MSM_MessageManager_RPORT: required-interface=Service/MessageManager
      Vehicle_MSM_ModemManager_RPORT: required-interface=Service/ModemManager
      Vehicle_MSM_NetworkManager_RPORT: required-interface=NetworkManager
      Vehicle_MSM_SimManager_RPORT: required-interface=Service/SimManager
      Vehicle_SDE_SelfDiagnosis_RPORT: required-interface=SelfDiagnosis
      Vehicle_SM_StateManager_RPORT: required-interface=StateManager
      Vehicle_SOAAdaptor_Body1_RPORT: required-interface=Body1
      Vehicle_SOAAdaptor_Body2_RPORT: required-interface=Body2
      Vehicle_SOAAdaptor_CANoverIP_RPORT: required-interface=CANoverIP
      Vehicle_SOAAdaptor_Chassis_RPORT: required-interface=Chassis
      Vehicle_SOAAdaptor_DataCollection_RPORT: required-interface=DataCollection
      Vehicle_SOAAdaptor_Extended_RPORT: required-interface=Extended
      Vehicle_SOAAdaptor_Location_RPORT: required-interface=Location
      Vehicle_SOAAdaptor_MultiMedia_RPORT: required-interface=MultiMedia
      Vehicle_SOAAdaptor_PowerTrain1_RPORT: required-interface=PowerTrain1
      Vehicle_SOAAdaptor_PowerTrain2_RPORT: required-interface=PowerTrain2
      Vehicle_Security_SecureFlash2_RPORT: required-interface=SecureFlash2
      Vehicle_Telemanager_Communicator_RPORT: required-interface=Service/Communicator
      Vehicle_Telemanager_HTTPSimple_RPORT: required-interface=HTTPSimple
      Vehicle_Telemanager_HTTP_RPORT: required-interface=HTTP
      Vehicle_Telemanager_MQTT_RPORT: required-interface=MQTT
      Vehicle_Telemanager_MobileMessage_RPORT: required-interface=MobileMessage
      Vehicle_Telemanager_Provisioning_RPORT: required-interface=Provisioning
    provide port Vehicle_VAM_Mode_PPORT: provided-interface=Mode
    require port Vehicle_VAS_VehicleAPI_RPORT: required-interface=VehicleAPI
    require port Vehicle_Vcc_Manager_RPORT: required-interface=Service/Manager
  adaptive application sw component type VAS
    9 x require port:
      Vehicle_CCS_Monitoring_RPORT: required-interface=Monitoring
      Vehicle_SOAAdaptor_Body1_RPORT: required-interface=Body1
      Vehicle_SOAAdaptor_Body2_RPORT: required-interface=Body2
      Vehicle_SOAAdaptor_CANoverIP_RPORT: required-interface=CANoverIP
      Vehicle_SOAAdaptor_Chassis_RPORT: required-interface=Chassis
      Vehicle_SOAAdaptor_Extended_RPORT: required-interface=Extended
      Vehicle_SOAAdaptor_MultiMedia_RPORT: required-interface=MultiMedia
      Vehicle_SOAAdaptor_PowerTrain1_RPORT: required-interface=PowerTrain1
      Vehicle_SOAAdaptor_PowerTrain2_RPORT: required-interface=PowerTrain2
    provide port Vehicle_VAS_VehicleAPI_PPORT: provided-interface=VehicleAPI
  adaptive application sw component type VCRM
    28 x require port:
      CCU_Vehicle_DiagnosticService_RPORT: required-interface=DiagnosticService
      Info_Cloud_EngineeringMode_RPORT: required-interface=Service/EngineeringMode
      Info_Location_GNSS_RPORT: required-interface=GNSS
      Info_Location_MapMatching_RPORT: required-interface=MapMatching
      Info_Location_Time_RPORT: required-interface=Service/Time
      Info_System_EngineeringMode_RPORT: required-interface=Service/EngineeringMode
      Vehicle_ApSysMgr_IOManager_RPORT: required-interface=IOManager
      Vehicle_ApSysMgr_NetManager_RPORT: required-interface=Service/NetManager
      Vehicle_ApSysMgr_SysInfoManager_RPORT: required-interface=SysInfoManager
      Vehicle_ApSysMgr_TimeManager_RPORT: required-interface=TimeManager
      Vehicle_DPM_Policy_RPORT: required-interface=Service/Policy
      Vehicle_DiagMgr_RoutingDiag_RPORT: required-interface=RoutingDiag
      Vehicle_EthHandler_EthernetSwitchMgr_RPORT: required-interface=EthernetSwitchMgr
      Vehicle_EthNM_NM_RPORT: required-interface=NM
      Vehicle_SM_StateManager_RPORT: required-interface=StateManager
      Vehicle_SOAAdaptor_DataCollection_RPORT: required-interface=DataCollection
      Vehicle_SOAAdaptor_Location_RPORT: required-interface=Location
      Vehicle_Security_SecureFlash2_RPORT: required-interface=SecureFlash2
      Vehicle_SharedStorage_Share_RPORT: required-interface=Service/Share
      Vehicle_SharedStorage_Status_RPORT: required-interface=Status
      Vehicle_Telemanager_HTTPSimple_RPORT: required-interface=HTTPSimple
      Vehicle_Telemanager_HTTP_RPORT: required-interface=HTTP
      Vehicle_Telemanager_MQTT_RPORT: required-interface=MQTT
      Vehicle_Telemanager_Provisioning_RPORT: required-interface=Provisioning
      Vehicle_UpdateMaster_PackageManagement_RPORT: required-interface=Service/PackageManagement
      Vehicle_Vcc_Manager_RPORT: required-interface=Service/Manager
      Vehicle_Vcc_NetworkStatistics_RPORT: required-interface=NetworkStatistics
      Vehicle_Vcc_Policy_RPORT: required-interface=Service/Policy
  adaptive application sw component type VSM
    12 x require port:
      Vehicle_ApSysMgr_IOManager_RPORT: required-interface=IOManager
      Vehicle_ApSysMgr_SysInfoManager_RPORT: required-interface=SysInfoManager
      Vehicle_SM_StateManager_RPORT: required-interface=StateManager
      Vehicle_SOAAdaptor_Body1_RPORT: required-interface=Body1
      Vehicle_SOAAdaptor_Body2_RPORT: required-interface=Body2
      Vehicle_SOAAdaptor_CANoverIP_RPORT: required-interface=CANoverIP
      Vehicle_SOAAdaptor_Chassis_RPORT: required-interface=Chassis
      Vehicle_SOAAdaptor_Extended_RPORT: required-interface=Extended
      Vehicle_SOAAdaptor_Location_RPORT: required-interface=Location
      Vehicle_SOAAdaptor_MultiMedia_RPORT: required-interface=MultiMedia
      Vehicle_SOAAdaptor_PowerTrain1_RPORT: required-interface=PowerTrain1
      Vehicle_SOAAdaptor_PowerTrain2_RPORT: required-interface=PowerTrain2
    provide port Vehicle_VSM_SafeStatusManagement_PPORT: provided-interface=SafeStatusManagement
    require port Vehicle_Vcc_Manager_RPORT: required-interface=Service/Manager
  adaptive application sw component type VSUA
    19 x require port:
      ARA_UCM_PackageManagement_RPORT: required-interface=Service/PackageManagement
      Info_Update_RFSManager_RPORT: required-interface=RFSManager
      Update_USS_UpdateStandard_RPORT: required-interface=UpdateStandard
      Vehicle_ApSysMgr_IOManager_RPORT: required-interface=IOManager
      Vehicle_ApSysMgr_NetManager_RPORT: required-interface=Service/NetManager
      Vehicle_ApSysMgr_SysInfoManager_RPORT: required-interface=SysInfoManager
      Vehicle_BSM_BootSyncManager_RPORT: required-interface=BootSyncManager
      Vehicle_CM_PackageManagement_RPORT: required-interface=Service/PackageManagement
      Vehicle_DiagMgr_RoutingDiag_RPORT: required-interface=RoutingDiag
      Vehicle_FlashingAdaptor_PackageManagement_RPORT: required-interface=Service/PackageManagement
      Vehicle_LogCollection_DebugSnapshot_RPORT: required-interface=DebugSnapshot
      Vehicle_RFSM_RemoteFileSystemManager_RPORT: required-interface=RemoteFileSystemManager
      Vehicle_SDE_SelfDiagnosis_RPORT: required-interface=SelfDiagnosis
      Vehicle_SOAAdaptor_Body1_RPORT: required-interface=Body1
      Vehicle_SOAAdaptor_CANoverIP_RPORT: required-interface=CANoverIP
      Vehicle_SOAAdaptor_PowerTrain1_RPORT: required-interface=PowerTrain1
      Vehicle_SOAAdaptor_PowerTrain2_RPORT: required-interface=PowerTrain2
      Vehicle_Security_ASKMaster_RPORT: required-interface=ASKMaster
      Vehicle_UpdateMaster_PackageManagement_RPORT: required-interface=Service/PackageManagement
    provide port Vehicle_VSUA_UdsReprogram_PPORT: provided-interface=UdsReprogram
  adaptive application sw component type Vcc
    provide port CCU_ExternalNetwork_Manager2_PPORT: provided-interface=Manager2
    10 x require port:
      Vehicle_ApSysMgr_SysInfoManager_RPORT: required-interface=SysInfoManager
      Vehicle_CCS_Monitoring_RPORT: required-interface=Monitoring
      Vehicle_DPM_Policy_RPORT: required-interface=Service/Policy
      Vehicle_EthHandler_EthernetSwitchMgr_RPORT: required-interface=EthernetSwitchMgr
      Vehicle_LogCollection_DebugSnapshot_RPORT: required-interface=DebugSnapshot
      Vehicle_LogCollection_Logging_RPORT: required-interface=Logging
      Vehicle_MSM_APNManager_RPORT: required-interface=APNManager
      Vehicle_MSM_NetworkManager_RPORT: required-interface=NetworkManager
      Vehicle_MSM_SimManager_RPORT: required-interface=Service/SimManager
      Vehicle_SDE_SelfDiagnosis_RPORT: required-interface=SelfDiagnosis
    4 x provide port:
      Vehicle_Vcc_Manager_PPORT: provided-interface=Service/Manager
      Vehicle_Vcc_NetworkStatistics_PPORT: provided-interface=NetworkStatistics
      Vehicle_Vcc_Policy_PPORT: provided-interface=Service/Policy
      Vehicle_Vcc_ServiceGroup_PPORT: provided-interface=ServiceGroup
package /SwComponent/Composition
  composition sw component type CCU
    39 x component:
      ApSysMgr: type=ApSysMgr
      BSM: type=BSM
      CCS: type=CCS
      CIDS: type=CIDS
      CM: type=CM
      DPM: type=DPM
      DiagMgr: type=DiagMgr
      EIDS: type=EIDS
      EthHandler: type=EthHandler
      EthNM: type=EthNM
      FlashingAdaptor: type=FlashingAdaptor
      FoDClient: type=FoDClient
      FoDMaster: type=FoDMaster
      IPCHandler: type=IPCHandler
      LogCollection: type=LogCollection
      MSM: type=MSM
      NSD: type=NSD
      OtaClient: type=OtaClient
      PHM: type=PHM
      RFSM: type=RFSM
      RTA: type=RTA
      SDE: type=SDE
      SM: type=SM
      SOAAdaptor: type=SOAAdaptor
      Security: type=Security
      SelfUpdateEngine: type=SelfUpdateEngine
      SharedStorage: type=SharedStorage
      TAD: type=TAD
      Telemanager: type=Telemanager
      TraceEngine: type=TraceEngine
      UCM: type=UCM
      UMT: type=UMT
      UpdateMaster: type=UpdateMaster
      VAM: type=VAM
      VAS: type=VAS
      VCRM: type=VCRM
      VSM: type=VSM
      VSUA: type=VSUA
      Vcc: type=Vcc
  composition sw component type System
    component CCU: type=CCU
package /DataType/Implementation/CPP
  968 x std cpp implementation data type:
    ACNSignal: category=STRUCTURE, type-emitter=TYPE_EMITTER_ARA
      namespaces:
        symbol props CCU
        symbol props Vehicle
        symbol props S2S
      cpp implementation data type element signalItem: type-reference={inplace=false, type-reference=ACNSignal_toIP}
      cpp implementation data type element signalValue: type-reference={inplace=false, type-reference=uint32_t}
    ACNSignal_toIP: compu {texttable}, range raw 0..15, type-emitter=TYPE_EMITTER_ARA, type-reference=uint32_t
      namespaces:
        symbol props CCU
        symbol props Vehicle
        symbol props S2S
    APNConnectionStatus_EventData: category=STRUCTURE, type-emitter=TYPE_EMITTER_ARA
      namespaces:
        symbol props Vehicle
        symbol props MSM
        symbol props APNManager
      cpp implementation data type element apn: type-reference={inplace=false, type-reference=String}
      cpp implementation data type element status: type-reference={inplace=false, type-reference=APNStatus}
    APNInfo_EventData: category=STRUCTURE, type-emitter=TYPE_EMITTER_ARA
      namespaces:
        symbol props Vehicle
        symbol props MSM
        symbol props APNManager
      cpp implementation data type element Information: type-reference={inplace=false, type-reference=APNInformation}
      cpp implementation data type element apn: type-reference={inplace=false, type-reference=String}
    APNInformation: category=STRUCTURE, type-emitter=TYPE_EMITTER_ARA
      namespaces:
        symbol props Vehicle
        symbol props MSM
        symbol props APNManager
      10 x cpp implementation data type element, all with type-reference={inplace=false, type-reference=String}:
        ipv4Addr
        ipv4GateWay
        ipv6Addr
        ipv6GateWay
        ipv4PrimaryDNS
        apn
        ipv4SecondaryDNS
        ipv6PrimaryDNS
        ivnSettingsInterface
        ipv6SecondaryDNS
    APNStatus: compu {texttable}, range raw 0..3, type-emitter=TYPE_EMITTER_ARA, type-reference=uint32_t
      namespaces:
        symbol props Vehicle
        symbol props MSM
        symbol props APNManager
    APSysInfo: category=STRUCTURE, type-emitter=TYPE_EMITTER_ARA
      namespaces:
        symbol props Vehicle
        symbol props IPCHandler
        symbol props RoutingIPC
      cpp implementation data type element apVersion: type-reference={inplace=false, type-reference=String}
      cpp implementation data type element eswVersion: type-reference={inplace=false, type-reference=String}
    ARLTableItem: category=STRUCTURE, type-emitter=TYPE_EMITTER_ARA
      namespaces:
        symbol props CCU
        symbol props ExternalNetwork
        symbol props Manager2
      cpp implementation data type element ip_address: type-reference={inplace=false, type-reference=String}
      cpp implementation data type element mac_address: type-reference={inplace=false, type-reference=String}
    ASKErrCode: compu {texttable}, range raw 0..2, type-emitter=TYPE_EMITTER_ARA, type-reference=uint32_t
      namespaces:
        symbol props Vehicle
        symbol props Security
        symbol props ASKMaster
    AccessToken: category=STRUCTURE, type-emitter=TYPE_EMITTER_ARA
      namespaces:
        symbol props Vehicle
        symbol props Telemanager
        symbol props Provisioning
      cpp implementation data type element scope: type-reference={inplace=false, type-reference=AccessTokenScope}
      cpp implementation data type element validity: type-reference={inplace=false, type-reference=CPP/CCResult}
      cpp implementation data type element val: type-reference={inplace=false, type-reference=String}
    AccessTokenScope: compu {texttable}, range raw 0..2, type-emitter=TYPE_EMITTER_ARA, type-reference=uint32_t
      namespaces:
        symbol props Vehicle
        symbol props Telemanager
        symbol props Provisioning
    ActionLists_VECTOR: category=VECTOR, cpp-template-argument=CPP/LogAction, type-emitter=TYPE_EMITTER_ARA
      namespaces:
        symbol props Info
        symbol props System
        symbol props EngineeringMode
    ActionType: compu {texttable}, range raw 0..2, type-emitter=TYPE_EMITTER_ARA, type-reference=uint32_t
      namespaces:
        symbol props Vehicle
        symbol props CM
        symbol props PackageManagement
    ActionType: compu {texttable}, range raw 0..2, type-emitter=TYPE_EMITTER_ARA, type-reference=uint32_t
      namespaces:
        symbol props ara
        symbol props ucm
        symbol props pkgmgr
    ActivateAPNType: compu {texttable}, range raw 0..3, type-emitter=TYPE_EMITTER_ARA, type-reference=uint32_t
      namespaces:
        symbol props Vehicle
        symbol props MSM
        symbol props APNManager
    Activity_VECTOR: category=VECTOR, cpp-template-argument=ServiceGroupsActivity, type-emitter=TYPE_EMITTER_ARA
      namespaces:
        symbol props CCU
        symbol props ExternalNetwork
        symbol props Manager2
    AddContextError: compu {texttable}, range raw 0..3, type-emitter=TYPE_EMITTER_ARA, type-reference=uint32_t
      namespaces:
        symbol props DCU
        symbol props Telephony
        symbol props MessageManager
    AddContextError: compu {texttable}, range raw 0..3, type-emitter=TYPE_EMITTER_ARA, type-reference=uint32_t
      namespaces:
        symbol props DCU
        symbol props Telephony
        symbol props EngineeringMode
    AddContextError: compu {texttable}, range raw 0..3, type-emitter=TYPE_EMITTER_ARA, type-reference=uint32_t
      namespaces:
        symbol props DCU
        symbol props Telephony
        symbol props VoiceCallManager
    AddContextError: compu {texttable}, range raw 0..3, type-emitter=TYPE_EMITTER_ARA, type-reference=uint32_t
      namespaces:
        symbol props DCU
        symbol props Telephony
        symbol props SimManager
    AddContextError: compu {texttable}, range raw 0..3, type-emitter=TYPE_EMITTER_ARA, type-reference=uint32_t
      namespaces:
        symbol props DCU
        symbol props Telephony
        symbol props ConnectionContext
    AddContextError: compu {texttable}, range raw 0..3, type-emitter=TYPE_EMITTER_ARA, type-reference=uint32_t
      namespaces:
        symbol props DCU
        symbol props Telephony
        symbol props ConnectionManager
    AddContextError: compu {texttable}, range raw 0..3, type-emitter=TYPE_EMITTER_ARA, type-reference=uint32_t
      namespaces:
        symbol props DCU
        symbol props Telephony
        symbol props NetworkInformation
    AddContextError: compu {texttable}, range raw 0..3, type-emitter=TYPE_EMITTER_ARA, type-reference=uint32_t
      namespaces:
        symbol props DCU
        symbol props Telephony
        symbol props ModemManager
    AgreeType: compu {texttable}, range raw 0..2, type-emitter=TYPE_EMITTER_ARA, type-reference=uint32_t
      namespaces:
        symbol props CCU
        symbol props Mode
        symbol props Routines
    AgreementInfo: category=STRUCTURE, type-emitter=TYPE_EMITTER_ARA
      namespaces:
        symbol props CCU
        symbol props Mode
        symbol props Routines
      cpp implementation data type element agreeType: type-reference={inplace=false, type-reference=AgreeType}  # Agreement Type
      cpp implementation data type element routineId: type-reference={inplace=false, type-reference=uint32_t}  # Routine ID
      cpp implementation data type element agreeId: type-reference={inplace=false, type-reference=uint32_t}  # Agreement ID
    AirplaneMode: compu {texttable}, range raw 0..3, type-emitter=TYPE_EMITTER_ARA, type-reference=uint32_t
      namespaces:
        symbol props DCU
        symbol props Telephony
        symbol props ModemManager
    AirplaneModeType: compu {texttable}, range raw 0..3, type-emitter=TYPE_EMITTER_ARA, type-reference=uint32_t
      namespaces:
        symbol props Vehicle
        symbol props MSM
        symbol props ModemManager
    AlertLog: category=STRUCTURE, type-emitter=TYPE_EMITTER_ARA
      namespaces:
        symbol props Vehicle
        symbol props CIDS
        symbol props ReportSender
      cpp implementation data type element alertNum: type-reference={inplace=false, type-reference=uint64_t}
      cpp implementation data type element report: type-reference={inplace=false, type-reference=ByteArray}
    AlertLog: category=STRUCTURE, type-emitter=TYPE_EMITTER_ARA
      namespaces:
        symbol props Vehicle
        symbol props EIDS
        symbol props ReportSender
      cpp implementation data type element alertNum: type-reference={inplace=false, type-reference=uint64_t}
      cpp implementation data type element report: type-reference={inplace=false, type-reference=ByteArray}
    AllCanNetStatus: compu {texttable}, range raw 0..5, type-emitter=TYPE_EMITTER_ARA, type-reference=uint32_t
      namespaces:
        symbol props Vehicle
        symbol props ApSysMgr
        symbol props NetManager
    AntennaConnection: compu {texttable}, range raw 0..3, type-emitter=TYPE_EMITTER_ARA, type-reference=uint32_t
      namespaces:
        symbol props DCU
        symbol props Telephony
        symbol props ModemManager
    ApEthNetStatus: compu {texttable}, range raw 0..7, type-emitter=TYPE_EMITTER_ARA, type-reference=uint32_t
      namespaces:
        symbol props Vehicle
        symbol props IPCHandler
        symbol props RoutingIPC
    ApnType: compu {texttable}, range raw 0..6, type-emitter=TYPE_EMITTER_ARA, type-reference=uint32_t
      namespaces:
        symbol props Vehicle
        symbol props Vcc
        symbol props Policy
    ApnTypeMap: category=ASSOCIATIVE_MAP, type-emitter=TYPE_EMITTER_ARA
      namespaces:
        symbol props Vehicle
        symbol props Vcc
        symbol props Policy
      template-arguments:
        category=ASSOC_MAP_KEY, template-type=CPP/GroupTypes
        category=ASSOC_MAP_VALUE, template-type=ApnType
    AppIVDHashType: category=STRUCTURE, type-emitter=TYPE_EMITTER_ARA
      namespaces:
        symbol props Vehicle
        symbol props CM
        symbol props PackageManagement
      cpp implementation data type element AppID: type-reference={inplace=false, type-reference=String}
      cpp implementation data type element IVDHash: type-reference={inplace=false, type-reference=ByteArray}
    AppIVDHashType: category=STRUCTURE, type-emitter=TYPE_EMITTER_ARA
      namespaces:
        symbol props ara
        symbol props ucm
        symbol props pkgmgr
      cpp implementation data type element AppID: type-reference={inplace=false, type-reference=String}
      cpp implementation data type element IVDHash: type-reference={inplace=false, type-reference=ByteArray}
    AppIVDHashVectorType: category=VECTOR, cpp-template-argument=CPP/AppIVDHashType, type-emitter=TYPE_EMITTER_ARA
      namespaces:
        symbol props Vehicle
        symbol props CM
        symbol props PackageManagement
    AppIVDHashVectorType: category=VECTOR, cpp-template-argument=CPP/AppIVDHashType, type-emitter=TYPE_EMITTER_ARA
      namespaces:
        symbol props ara
        symbol props ucm
        symbol props pkgmgr
    AppModeType: category=STRUCTURE, type-emitter=TYPE_EMITTER_ARA
      namespaces:
        symbol props Vehicle
        symbol props ApSysMgr
        symbol props NetManager
      cpp implementation data type element appModeOta: type-reference={inplace=false, type-reference=OtaModeType}
      cpp implementation data type element appModeFod: type-reference={inplace=false, type-reference=FodModeType}
    ApprovalInfo: category=STRUCTURE, type-emitter=TYPE_EMITTER_ARA
      namespaces:
        symbol props Info
        symbol props Update
        symbol props InteractionManager
      cpp implementation data type element ReleaseID: type-reference={inplace=false, type-reference=String}  # a unique identifier for the software release
      cpp implementation data type element props: type-reference={inplace=false, type-reference=CPP/KeyValueMap}  # The list of keys defined in the KeyValueMap props is as follows:1. "download" : contains the information of the user's agreement to download.- "OK" / "NOK" / "LATER"2. "install": contains the information of the user's agreement to install.- "OK" / "NOK" / "LATER"3. "donotshowagain": contains the user's preference not to show again.- "TRUE" / "FALSE"
    AsyncServerReportRequested_EventData: category=STRUCTURE, type-emitter=TYPE_EMITTER_ARA
      namespaces:
        symbol props Vehicle
        symbol props UpdateMaster
        symbol props PackageManagement
      cpp implementation data type element detail: type-reference={inplace=false, type-reference=StringMap}
    AuthLevelType: compu {texttable}, range raw 0..2, type-emitter=TYPE_EMITTER_ARA, type-reference=uint32_t
      namespaces:
        symbol props Update
        symbol props USS
        symbol props UpdateStandard
    AuthLevelType: compu {texttable}, range raw 0..2, type-emitter=TYPE_EMITTER_ARA, type-reference=uint32_t
      namespaces:
        symbol props Vehicle
        symbol props SDE
        symbol props SelfDiagnosis
    Availability: compu {texttable}, range raw 0..2, type-emitter=TYPE_EMITTER_ARA, type-reference=uint32_t
      namespaces:
        symbol props Vehicle
        symbol props VAS
        symbol props VehicleAPI
    AvailableLanguages_VECTOR: category=VECTOR, cpp-template-argument=int32_t, type-emitter=TYPE_EMITTER_ARA
      namespaces:
        symbol props Info
        symbol props Setup
        symbol props GeneralSettings
    AverageFuelEconomyInfo: category=STRUCTURE, type-emitter=TYPE_EMITTER_ARA
      namespaces:
        symbol props Info
        symbol props Cluster
        symbol props InformationProvider
      cpp implementation data type element type: type-reference={inplace=false, type-reference=String}
      cpp implementation data type element average: type-reference={inplace=false, type-reference=float}
      cpp implementation data type element unit: type-reference={inplace=false, type-reference=FuelEconomyUnit}
    AverageFuelEconomyStrInfo: category=STRUCTURE, type-emitter=TYPE_EMITTER_ARA
      namespaces:
        symbol props Info
        symbol props Cluster
        symbol props InformationProvider
      cpp implementation data type element type: type-reference={inplace=false, type-reference=String}
      cpp implementation data type element averageStr: type-reference={inplace=false, type-reference=String}
      cpp implementation data type element unit: type-reference={inplace=false, type-reference=FuelEconomyUnit}
    AverageFuelEconomyStr_VECTOR: category=VECTOR, cpp-template-argument=AverageFuelEconomyStrInfo, type-emitter=TYPE_EMITTER_ARA
      namespaces:
        symbol props Info
        symbol props Cluster
        symbol props InformationProvider
    AverageFuelEconomy_VECTOR: category=VECTOR, cpp-template-argument=AverageFuelEconomyInfo, type-emitter=TYPE_EMITTER_ARA
      namespaces:
        symbol props Info
        symbol props Cluster
        symbol props InformationProvider
    BSMErrorType: compu {texttable}, range raw 0..5, type-emitter=TYPE_EMITTER_ARA, type-reference=uint32_t
      namespaces:
        symbol props Vehicle
        symbol props BSM
        symbol props BootSyncManager
    BatWarnSignal: category=STRUCTURE, type-emitter=TYPE_EMITTER_ARA
      namespaces:
        symbol props CCU
        symbol props Vehicle
        symbol props S2S
      cpp implementation data type element signalItem: type-reference={inplace=false, type-reference=BatWarnSignal_toIP}
      cpp implementation data type element signalValue: type-reference={inplace=false, type-reference=uint32_t}
    BatWarnSignal_toIP: compu {texttable}, range raw 0, type-emitter=TYPE_EMITTER_ARA, type-reference=uint32_t
      namespaces:
        symbol props CCU
        symbol props Vehicle
        symbol props S2S
    BltnCamStatus: compu {texttable}, range raw 0..1, type-emitter=TYPE_EMITTER_ARA, type-reference=uint32_t
      namespaces:
        symbol props BltnCam
        symbol props System
        symbol props Manager
    BootMode: compu {texttable}, range raw 0..255, type-emitter=TYPE_EMITTER_ARA, type-reference=uint32_t
      namespaces:
        symbol props Vehicle
        symbol props ApSysMgr
        symbol props BootModeManager
    BusAndMessageId: category=STRUCTURE, type-emitter=TYPE_EMITTER_ARA
      namespaces:
        symbol props Vehicle
        symbol props SOAAdaptor
        symbol props DataCollection
      cpp implementation data type element busId: type-reference={inplace=false, type-reference=uint8_t}
      cpp implementation data type element messageId: type-reference={inplace=false, type-reference=uint32_t}
    BusAndMessageId_DR: category=STRUCTURE, type-emitter=TYPE_EMITTER_ARA
      namespaces:
        symbol props Vehicle
        symbol props SOAAdaptor
        symbol props DynamicRouting
      cpp implementation data type element busId: type-reference={inplace=false, type-reference=CANBus}
      cpp implementation data type element messageId: type-reference={inplace=false, type-reference=uint32_t}
    BusLoad: category=STRUCTURE, type-emitter=TYPE_EMITTER_ARA
      namespaces:
        symbol props Vehicle
        symbol props IPCHandler
        symbol props RoutingIPC
      8 x cpp implementation data type element, all with type-reference={inplace=false, type-reference=uint8_t}:
        loadFDB1
        loadFDB2
        loadFDM
        loadFDP1
        loadFDP2
        loadFDC
        loadFDE
        loadFDI
    BusLoadInfoType: category=STRUCTURE, type-emitter=TYPE_EMITTER_ARA
      namespaces:
        symbol props Vehicle
        symbol props FlashingAdaptor
        symbol props PackageManagement
      4 x cpp implementation data type element:
        busName: type-reference={inplace=false, type-reference=String}
        busLoadThreshold: type-reference={inplace=false, type-reference=uint8_t}
        cstminh: type-reference={inplace=false, type-reference=uint8_t}
        cstminl: type-reference={inplace=false, type-reference=uint8_t}
    ByteArray: category=VECTOR, cpp-template-argument=uint8_t, type-emitter=TYPE_EMITTER_ARA
    ByteMap: category=ASSOCIATIVE_MAP, template-arguments=[{category=ASSOC_MAP_KEY, template-type=String}, {category=ASSOC_MAP_VALUE, template-type=ByteArray}], type-emitter=TYPE_EMITTER_ARA
      namespaces:
        symbol props Info
        symbol props Update
        symbol props InteractionManager
    ByteVectorType: category=VECTOR, cpp-template-argument=uint8_t, type-emitter=TYPE_EMITTER_ARA
    CANBus: compu {texttable}, range raw 0..12, type-emitter=TYPE_EMITTER_ARA, type-reference=uint32_t
      namespaces:
        symbol props Vehicle
        symbol props SOAAdaptor
        symbol props DynamicRouting
    CANStatus: compu {texttable}, range raw 0..1, type-emitter=TYPE_EMITTER_ARA, type-reference=uint32_t
      namespaces:
        symbol props Vehicle
        symbol props SOAAdaptor
        symbol props Body1
    CANStatus: compu {texttable}, range raw 0..1, type-emitter=TYPE_EMITTER_ARA, type-reference=uint32_t
      namespaces:
        symbol props Vehicle
        symbol props SOAAdaptor
        symbol props PowerTrain1
    CANStatus: compu {texttable}, range raw 0..1, type-emitter=TYPE_EMITTER_ARA, type-reference=uint32_t
      namespaces:
        symbol props Vehicle
        symbol props SOAAdaptor
        symbol props Body2
    CANStatus: compu {texttable}, range raw 0..1, type-emitter=TYPE_EMITTER_ARA, type-reference=uint32_t
      namespaces:
        symbol props Vehicle
        symbol props SOAAdaptor
        symbol props Extended
    CANStatus: compu {texttable}, range raw 0..1, type-emitter=TYPE_EMITTER_ARA, type-reference=uint32_t
      namespaces:
        symbol props Vehicle
        symbol props SOAAdaptor
        symbol props PowerTrain2
    CANStatus: compu {texttable}, range raw 0..1, type-emitter=TYPE_EMITTER_ARA, type-reference=uint32_t
      namespaces:
        symbol props Vehicle
        symbol props SOAAdaptor
        symbol props MultiMedia
    CANStatus: compu {texttable}, range raw 0..1, type-emitter=TYPE_EMITTER_ARA, type-reference=uint32_t
      namespaces:
        symbol props Vehicle
        symbol props SOAAdaptor
        symbol props Chassis
    CCConnectionState: compu {texttable}, range raw 0..5, type-emitter=TYPE_EMITTER_ARA, type-reference=uint32_t
      namespaces:
        symbol props Vehicle
        symbol props Telemanager
        symbol props MQTT
    CCDict: category=STRUCTURE, type-emitter=TYPE_EMITTER_ARA
      namespaces:
        symbol props Vehicle
        symbol props Telemanager
        symbol props MobileMessage
      cpp implementation data type element head: type-reference={inplace=false, type-reference=String}
      cpp implementation data type element val: type-reference={inplace=false, type-reference=String}
    CCDict: category=STRUCTURE, type-emitter=TYPE_EMITTER_ARA
      namespaces:
        symbol props Vehicle
        symbol props Telemanager
        symbol props HTTP
      cpp implementation data type element head: type-reference={inplace=false, type-reference=String}
      cpp implementation data type element val: type-reference={inplace=false, type-reference=String}
    CCDict: category=STRUCTURE, type-emitter=TYPE_EMITTER_ARA
      namespaces:
        symbol props Vehicle
        symbol props Telemanager
        symbol props HTTP_Simple
      cpp implementation data type element head: type-reference={inplace=false, type-reference=String}
      cpp implementation data type element val: type-reference={inplace=false, type-reference=String}
    CCHTTPError: compu {texttable}, range raw 0..10, type-emitter=TYPE_EMITTER_ARA, type-reference=uint32_t
      namespaces:
        symbol props Vehicle
        symbol props Telemanager
        symbol props HTTP
    CCHTTPError: compu {texttable}, range raw 0..10, type-emitter=TYPE_EMITTER_ARA, type-reference=uint32_t
      namespaces:
        symbol props Vehicle
        symbol props Telemanager
        symbol props HTTP_Simple
    CCHTTPMethod: compu {texttable}, range raw 0..4, type-emitter=TYPE_EMITTER_ARA, type-reference=uint32_t
      namespaces:
        symbol props Vehicle
        symbol props Telemanager
        symbol props MobileMessage
    CCHTTPMethod: compu {texttable}, range raw 0..4, type-emitter=TYPE_EMITTER_ARA, type-reference=uint32_t
      namespaces:
        symbol props Vehicle
        symbol props Telemanager
        symbol props HTTP
    CCHTTPMethod: compu {texttable}, range raw 0..4, type-emitter=TYPE_EMITTER_ARA, type-reference=uint32_t
      namespaces:
        symbol props Vehicle
        symbol props Telemanager
        symbol props HTTP_Simple
    CCHTTPRequest: category=STRUCTURE, type-emitter=TYPE_EMITTER_ARA
      namespaces:
        symbol props Vehicle
        symbol props Telemanager
        symbol props MobileMessage
      7 x cpp implementation data type element:
        host: type-reference={inplace=false, type-reference=CPP/CCHost}
        uri: type-reference={inplace=false, type-reference=String}
        method: type-reference={inplace=false, type-reference=CPP/CCHTTPMethod}
        bodyType: type-reference={inplace=false, type-reference=String}
        bodyData: type-reference={inplace=false, type-reference=ByteArray}
        customHeaders: type-reference={inplace=false, type-reference=CPP/CCHTTPRequest_customHeaders_VECTOR}
        serviceGroup: type-reference={inplace=false, type-reference=CPP/CCServiceGroup}
    CCHTTPRequest: category=STRUCTURE, type-emitter=TYPE_EMITTER_ARA
      namespaces:
        symbol props Vehicle
        symbol props Telemanager
        symbol props HTTP
      7 x cpp implementation data type element:
        host: type-reference={inplace=false, type-reference=CPP/CCHost}
        uri: type-reference={inplace=false, type-reference=String}
        method: type-reference={inplace=false, type-reference=CPP/CCHTTPMethod}
        bodyType: type-reference={inplace=false, type-reference=String}
        customHeaders: type-reference={inplace=false, type-reference=CPP/CCHTTPRequest_customHeaders_VECTOR}
        serviceGroup: type-reference={inplace=false, type-reference=CPP/CCServiceGroup}
        bodyData: type-reference={inplace=false, type-reference=ByteArray}
    CCHTTPRequest: category=STRUCTURE, type-emitter=TYPE_EMITTER_ARA
      namespaces:
        symbol props Vehicle
        symbol props Telemanager
        symbol props HTTP_Simple
      7 x cpp implementation data type element:
        host: type-reference={inplace=false, type-reference=CPP/CCHost}
        uri: type-reference={inplace=false, type-reference=String}
        method: type-reference={inplace=false, type-reference=CPP/CCHTTPMethod}
        bodyType: type-reference={inplace=false, type-reference=String}
        bodyData: type-reference={inplace=false, type-reference=ByteArray}
        customHeaders: type-reference={inplace=false, type-reference=CPP/CCHTTPRequest_customHeaders_VECTOR}
        serviceGroup: type-reference={inplace=false, type-reference=CPP/CCServiceGroup}
    CCHTTPRequest_customHeaders_VECTOR: category=VECTOR, cpp-template-argument=CPP/CCDict, type-emitter=TYPE_EMITTER_ARA
      namespaces:
        symbol props Vehicle
        symbol props Telemanager
        symbol props MobileMessage
    CCHTTPRequest_customHeaders_VECTOR: category=VECTOR, cpp-template-argument=CPP/CCDict, type-emitter=TYPE_EMITTER_ARA
      namespaces:
        symbol props Vehicle
        symbol props Telemanager
        symbol props HTTP
    CCHTTPRequest_customHeaders_VECTOR: category=VECTOR, cpp-template-argument=CPP/CCDict, type-emitter=TYPE_EMITTER_ARA
      namespaces:
        symbol props Vehicle
        symbol props Telemanager
        symbol props HTTP_Simple
    CCHTTPResponse: category=STRUCTURE, type-emitter=TYPE_EMITTER_ARA
      namespaces:
        symbol props Vehicle
        symbol props Telemanager
        symbol props HTTP
      4 x cpp implementation data type element:
        httpResponseCode: type-reference={inplace=false, type-reference=uint32_t}
        bodyType: type-reference={inplace=false, type-reference=String}
        bodyData: type-reference={inplace=false, type-reference=ByteArray}
        respHeaders: type-reference={inplace=false, type-reference=CPP/CCHTTPResponse_respHeaders_VECTOR}
    CCHTTPResponse: category=STRUCTURE, type-emitter=TYPE_EMITTER_ARA
      namespaces:
        symbol props Vehicle
        symbol props Telemanager
        symbol props HTTP_Simple
      6 x cpp implementation data type element:
        httpResponseCode: type-reference={inplace=false, type-reference=uint32_t}
        resCode: type-reference={inplace=false, type-reference=uint32_t}
        resMsg: type-reference={inplace=false, type-reference=String}
        bodyType: type-reference={inplace=false, type-reference=String}
        bodyData: type-reference={inplace=false, type-reference=ByteArray}
        respHeaders: type-reference={inplace=false, type-reference=CPP/CCHTTPResponse_respHeaders_VECTOR}
    CCHTTPResponse_respHeaders_VECTOR: category=VECTOR, cpp-template-argument=CPP/CCDict, type-emitter=TYPE_EMITTER_ARA
      namespaces:
        symbol props Vehicle
        symbol props Telemanager
        symbol props HTTP
    CCHTTPResponse_respHeaders_VECTOR: category=VECTOR, cpp-template-argument=CPP/CCDict, type-emitter=TYPE_EMITTER_ARA
      namespaces:
        symbol props Vehicle
        symbol props Telemanager
        symbol props HTTP_Simple
    CCHost: category=STRUCTURE, type-emitter=TYPE_EMITTER_ARA
      namespaces:
        symbol props Vehicle
        symbol props Telemanager
        symbol props MobileMessage
      cpp implementation data type element host: type-reference={inplace=false, type-reference=String}
      cpp implementation data type element port: type-reference={inplace=false, type-reference=uint32_t}
      cpp implementation data type element sslEnabled: type-reference={inplace=false, type-reference=bool}
    CCHost: category=STRUCTURE, type-emitter=TYPE_EMITTER_ARA
      namespaces:
        symbol props Vehicle
        symbol props Telemanager
        symbol props HTTP
      4 x cpp implementation data type element:
        host: type-reference={inplace=false, type-reference=String}
        port: type-reference={inplace=false, type-reference=uint32_t}
        timeout: type-reference={inplace=false, type-reference=uint32_t}
        sslEnabled: type-reference={inplace=false, type-reference=bool}
    CCHost: category=STRUCTURE, type-emitter=TYPE_EMITTER_ARA
      namespaces:
        symbol props Vehicle
        symbol props Telemanager
        symbol props Provisioning
      cpp implementation data type element host: type-reference={inplace=false, type-reference=String}
      cpp implementation data type element port: type-reference={inplace=false, type-reference=uint32_t}
      cpp implementation data type element sslEnabled: type-reference={inplace=false, type-reference=bool}
    CCHost: category=STRUCTURE, type-emitter=TYPE_EMITTER_ARA
      namespaces:
        symbol props Vehicle
        symbol props Telemanager
        symbol props HTTP_Simple
      4 x cpp implementation data type element:
        host: type-reference={inplace=false, type-reference=String}
        port: type-reference={inplace=false, type-reference=uint32_t}
        timeout: type-reference={inplace=false, type-reference=uint32_t}
        sslEnabled: type-reference={inplace=false, type-reference=bool}
    CCMQTTError: compu {texttable}, range raw 0..12, type-emitter=TYPE_EMITTER_ARA, type-reference=uint32_t
      namespaces:
        symbol props Vehicle
        symbol props Telemanager
        symbol props MQTT
    CCMQTTExtraPropertyInfo: category=STRUCTURE, type-emitter=TYPE_EMITTER_ARA
      namespaces:
        symbol props Vehicle
        symbol props Telemanager
        symbol props MQTT
      cpp implementation data type element response_topic: type-reference={inplace=false, type-reference=String}
    CCMQTTTopicInformation: category=STRUCTURE, type-emitter=TYPE_EMITTER_ARA
      namespaces:
        symbol props Vehicle
        symbol props Telemanager
        symbol props MQTT
      cpp implementation data type element topic: type-reference={inplace=false, type-reference=String}
      cpp implementation data type element qos: type-reference={inplace=false, type-reference=uint8_t}
    CCProvisioningContext: category=STRUCTURE, type-emitter=TYPE_EMITTER_ARA
      namespaces:
        symbol props Vehicle
        symbol props Telemanager
        symbol props Provisioning
      cpp implementation data type element vehicleID: type-reference={inplace=false, type-reference=String}
      cpp implementation data type element clientID: type-reference={inplace=false, type-reference=String}
    CCProvisioningStatus: compu {texttable}, range raw 0..9, type-emitter=TYPE_EMITTER_ARA, type-reference=uint32_t
      namespaces:
        symbol props Vehicle
        symbol props Telemanager
        symbol props Provisioning
    CCResult: compu {texttable}, range raw 0..15, type-emitter=TYPE_EMITTER_ARA, type-reference=uint32_t
      namespaces:
        symbol props Vehicle
        symbol props Telemanager
        symbol props MobileMessage
    CCResult: compu {texttable}, range raw 0..15, type-emitter=TYPE_EMITTER_ARA, type-reference=uint32_t
      namespaces:
        symbol props Vehicle
        symbol props Telemanager
        symbol props HTTP
    CCResult: compu {texttable}, range raw 0..15, type-emitter=TYPE_EMITTER_ARA, type-reference=uint32_t
      namespaces:
        symbol props Vehicle
        symbol props Telemanager
        symbol props Provisioning
    CCResult: compu {texttable}, range raw 0..15, type-emitter=TYPE_EMITTER_ARA, type-reference=uint32_t
      namespaces:
        symbol props Vehicle
        symbol props Telemanager
        symbol props MQTT
    CCSRequest: category=STRUCTURE, type-emitter=TYPE_EMITTER_ARA
      namespaces:
        symbol props CCU
        symbol props Cloud
        symbol props Communicator
      7 x cpp implementation data type element:
        serviceName: type-reference={inplace=false, type-reference=String}  # Destination Service Name (Reserved Field)
        timeStamp: type-reference={inplace=false, type-reference=String}  # Human readable datetime string "2020-09-10 10:20:30.0"
        msgID: type-reference={inplace=false, type-reference=String}  # Timestamp in which a 4byte integer is expressed in characters. However, If sending/receiving with SMS+ scheme, MSGID field is used for MSGID(4Byte) of SMS.
        transactionID: type-reference={inplace=false, type-reference=String}  # Transaction ID is assigned by the server
        scheme: type-reference={inplace=false, type-reference=String}
        status: type-reference={inplace=false, type-reference=MTMessageStatus}  # Processing status of CCS Request
        message: type-reference={inplace=false, type-reference=MofMessage}
    CCServiceGroup: compu {texttable}, range raw 0..11, type-emitter=TYPE_EMITTER_ARA, type-reference=uint32_t
      namespaces:
        symbol props Vehicle
        symbol props Telemanager
        symbol props MobileMessage
    CCServiceGroup: compu {texttable}, range raw 0..11, type-emitter=TYPE_EMITTER_ARA, type-reference=uint32_t
      namespaces:
        symbol props Vehicle
        symbol props Telemanager
        symbol props HTTP
    CCServiceGroup: compu {texttable}, range raw 0..11, type-emitter=TYPE_EMITTER_ARA, type-reference=uint32_t
      namespaces:
        symbol props Vehicle
        symbol props Telemanager
        symbol props HTTP_Simple
    CCUConfigType: category=STRUCTURE, type-emitter=TYPE_EMITTER_ARA
      namespaces:
        symbol props Vehicle
        symbol props UpdateMaster
        symbol props PackageManagement
      4 x cpp implementation data type element:
        CanId: type-reference={inplace=false, type-reference=String}
        Channel: type-reference={inplace=false, type-reference=String}
        Dual: type-reference={inplace=false, type-reference=DualType}
        NmPni: type-reference={inplace=false, type-reference=uint8_t}
    CCUConfigVectorType: category=VECTOR, cpp-template-argument=CCUConfigType, type-emitter=TYPE_EMITTER_ARA
      namespaces:
        symbol props Vehicle
        symbol props UpdateMaster
        symbol props PackageManagement
    CIDSAlertLog: category=STRUCTURE, type-emitter=TYPE_EMITTER_ARA
      namespaces:
        symbol props Vehicle
        symbol props CIDS
        symbol props CIDSDiagInfo
      6 x cpp implementation data type element:
        index: type-reference={inplace=false, type-reference=uint8_t}
        detectionTime: type-reference={inplace=false, type-reference=uint64_t}
        ruleId: type-reference={inplace=false, type-reference=uint8_t}
        busId: type-reference={inplace=false, type-reference=uint8_t}
        msgId: type-reference={inplace=false, type-reference=uint32_t}
        sigId: type-reference={inplace=false, type-reference=uint16_t}
    CIDSBusOffLog: category=STRUCTURE, type-emitter=TYPE_EMITTER_ARA
      namespaces:
        symbol props Vehicle
        symbol props CIDS
        symbol props CIDSDiagInfo
      5 x cpp implementation data type element:
        index: type-reference={inplace=false, type-reference=uint8_t}
        ruleId: type-reference={inplace=false, type-reference=uint8_t}
        detectionTime: type-reference={inplace=false, type-reference=uint64_t}
        busId: type-reference={inplace=false, type-reference=uint8_t}
        accumulatedTime: type-reference={inplace=false, type-reference=uint16_t}
    CIDSLogRetrieve_EventData: category=STRUCTURE, type-emitter=TYPE_EMITTER_ARA
      namespaces:
        symbol props Vehicle
        symbol props DPM
        symbol props Policy
      cpp implementation data type element newVersion: type-reference={inplace=false, type-reference=uint32_t}
    CIDSPolicyDownloaded_EventData: category=STRUCTURE, type-emitter=TYPE_EMITTER_ARA
      namespaces:
        symbol props Vehicle
        symbol props DPM
        symbol props Policy
      cpp implementation data type element newVersion: type-reference={inplace=false, type-reference=uint32_t}
    CIDSTimeOutLog: category=STRUCTURE, type-emitter=TYPE_EMITTER_ARA
      namespaces:
        symbol props Vehicle
        symbol props CIDS
        symbol props CIDSDiagInfo
      8 x cpp implementation data type element:
        index: type-reference={inplace=false, type-reference=uint8_t}
        drivingCycleId: type-reference={inplace=false, type-reference=uint8_t}
        detectionTime: type-reference={inplace=false, type-reference=uint64_t}
        ruleId: type-reference={inplace=false, type-reference=uint8_t}
        busId: type-reference={inplace=false, type-reference=uint8_t}
        msgId: type-reference={inplace=false, type-reference=uint32_t}
        ecuId: type-reference={inplace=false, type-reference=uint8_t}
        accumulatedTime: type-reference={inplace=false, type-reference=uint16_t}
    CallError: compu {texttable}, range raw 0..5, type-emitter=TYPE_EMITTER_ARA, type-reference=uint32_t
      namespaces:
        symbol props DCU
        symbol props Telephony
        symbol props VoiceCallManager
    CanIdVectorType: category=VECTOR, cpp-template-argument=String, type-emitter=TYPE_EMITTER_ARA
      namespaces:
        symbol props Vehicle
        symbol props FlashingAdaptor
        symbol props PackageManagement
    CanNetStatus: compu {texttable}, range raw 0..5, type-emitter=TYPE_EMITTER_ARA, type-reference=uint32_t
      namespaces:
        symbol props Vehicle
        symbol props IPCHandler
        symbol props RoutingIPC
    CanNetStatus: compu {texttable}, range raw 0..5, type-emitter=TYPE_EMITTER_ARA, type-reference=uint32_t
      namespaces:
        symbol props Vehicle
        symbol props ApSysMgr
        symbol props NetManager
    CapturedMessages_EventData: category=STRUCTURE, type-emitter=TYPE_EMITTER_ARA
      namespaces:
        symbol props Vehicle
        symbol props SOAAdaptor
        symbol props DataCollection
      cpp implementation data type element capturedMessages: type-reference={inplace=false, type-reference=CapturedMessages_capturedMessages_VECTOR}
    CapturedMessages_capturedMessages_VECTOR: category=VECTOR, cpp-template-argument=MessageInfo, type-emitter=TYPE_EMITTER_ARA
      namespaces:
        symbol props Vehicle
        symbol props SOAAdaptor
        symbol props DataCollection
    CertRole: category=STRUCTURE, type-emitter=TYPE_EMITTER_ARA
      namespaces:
        symbol props Update
        symbol props USS
        symbol props UpdateStandard
      cpp implementation data type element userRole: type-reference={inplace=false, type-reference=uint8_t}
      cpp implementation data type element diagRoutingRole: type-reference={inplace=false, type-reference=uint8_t}
    CertRole: category=STRUCTURE, type-emitter=TYPE_EMITTER_ARA
      namespaces:
        symbol props Vehicle
        symbol props SDE
        symbol props SelfDiagnosis
      cpp implementation data type element userRole: type-reference={inplace=false, type-reference=uint8_t}
      cpp implementation data type element diagRoutingRole: type-reference={inplace=false, type-reference=uint8_t}
    ChangeIVNRule_types_VECTOR: category=VECTOR, cpp-template-argument=String, type-emitter=TYPE_EMITTER_ARA
      namespaces:
        symbol props Vehicle
        symbol props Vcc
        symbol props Policy
    ChangePartialNetworkInfo_EventData: category=STRUCTURE, type-emitter=TYPE_EMITTER_ARA
      namespaces:
        symbol props Vehicle
        symbol props ApSysMgr
        symbol props NetManager
      cpp implementation data type element pncActivated: type-reference={inplace=false, type-reference=bool}
      cpp implementation data type element pnMap: type-reference={inplace=false, type-reference=ChangePartialNetworkInfo_pnMap_VECTOR}
    ChangePartialNetworkInfo_pnMap_VECTOR: category=VECTOR, cpp-template-argument=bool, type-emitter=TYPE_EMITTER_ARA
      namespaces:
        symbol props Vehicle
        symbol props ApSysMgr
        symbol props NetManager
    CidsAppInfo: category=STRUCTURE, type-emitter=TYPE_EMITTER_ARA
      namespaces:
        symbol props Vehicle
        symbol props CIDS
        symbol props CIDSInfo
      4 x cpp implementation data type element:
        vendorCode: type-reference={inplace=false, type-reference=String}
        connectivity: type-reference={inplace=false, type-reference=CPP/Connectivity}
        region: type-reference={inplace=false, type-reference=uint8_t}
        timeMode: type-reference={inplace=false, type-reference=CPP/TimeMode}
    CidsAppState: category=STRUCTURE, type-emitter=TYPE_EMITTER_ARA
      namespaces:
        symbol props Vehicle
        symbol props CIDS
        symbol props CIDSInfo
      5 x cpp implementation data type element, all with type-reference={inplace=false, type-reference=CPP/ModuleState}:
        appState
        engineState
        ruleState
        loggerState
        senderState
    CidsVersionInfo: category=STRUCTURE, type-emitter=TYPE_EMITTER_ARA
      namespaces:
        symbol props Vehicle
        symbol props CIDS
        symbol props CIDSInfo
      5 x cpp implementation data type element, all with type-reference={inplace=false, type-reference=String}:
        cidsVersion
        ruleVersion
        apVersion
        canDbVersion
        policyVersion
    ClientType: compu {texttable}, range raw 0..255, type-emitter=TYPE_EMITTER_ARA, type-reference=uint32_t
      namespaces:
        symbol props Vehicle
        symbol props FlashingAdaptor
        symbol props PackageManagement
    ClientType: compu {texttable}, range raw 0..255, type-emitter=TYPE_EMITTER_ARA, type-reference=uint32_t
      namespaces:
        symbol props Vehicle
        symbol props UpdateMaster
        symbol props PackageManagement
    CmOtaError: compu {texttable}, range raw 0..13, type-emitter=TYPE_EMITTER_ARA, type-reference=uint32_t
      namespaces:
        symbol props Vehicle
        symbol props CM
        symbol props OTA
    CmPolicyDownloaded_EventData: category=STRUCTURE, type-emitter=TYPE_EMITTER_ARA
      namespaces:
        symbol props Vehicle
        symbol props DPM
        symbol props Policy
      cpp implementation data type element newVersion: type-reference={inplace=false, type-reference=uint32_t}
    CommonSignal: category=STRUCTURE, type-emitter=TYPE_EMITTER_ARA
      namespaces:
        symbol props CCU
        symbol props Vehicle
        symbol props S2S
      cpp implementation data type element signalItem: type-reference={inplace=false, type-reference=CommonSignal_toIP}
      cpp implementation data type element signalValue: type-reference={inplace=false, type-reference=uint32_t}
    CommonSignal_toIP: compu {texttable}, range raw 0..2, type-emitter=TYPE_EMITTER_ARA, type-reference=uint32_t
      namespaces:
        symbol props CCU
        symbol props Vehicle
        symbol props S2S
    CommunicationState: category=STRUCTURE, type-emitter=TYPE_EMITTER_ARA
      namespaces:
        symbol props Vehicle
        symbol props SDE
        symbol props SelfDiagnosis
      cpp implementation data type element enableNM: type-reference={inplace=false, type-reference=bool}
      cpp implementation data type element enableNormal: type-reference={inplace=false, type-reference=bool}
    CommunicationType: compu {texttable}, range raw 1..3, type-emitter=TYPE_EMITTER_ARA, type-reference=uint32_t
      namespaces:
        symbol props Update
        symbol props USS
        symbol props UpdateStandard
    ConnectionContextItem: category=STRUCTURE, type-emitter=TYPE_EMITTER_ARA
      namespaces:
        symbol props DCU
        symbol props Telephony
        symbol props MessageManager
      27 x cpp implementation data type element:
        contextIndex: type-reference={inplace=false, type-reference=CPP/ContextIndex}
        contextPath: type-reference={inplace=false, type-reference=String}
        status: type-reference={inplace=false, type-reference=CPP/ContextStatus}
        deactivateReason: type-reference={inplace=false, type-reference=CPP/DeactivateReason}
        accessPointName: type-reference={inplace=false, type-reference=String}
        type: type-reference={inplace=false, type-reference=String}
        username: type-reference={inplace=false, type-reference=String}
        password: type-reference={inplace=false, type-reference=String}
        protocol: type-reference={inplace=false, type-reference=String}
        name: type-reference={inplace=false, type-reference=String}
        settings_Interface: type-reference={inplace=false, type-reference=String}
        settings_Method: type-reference={inplace=false, type-reference=String}
        settings_Address: type-reference={inplace=false, type-reference=String}
        settings_Netmask: type-reference={inplace=false, type-reference=String}
        settings_DomainNameServers: type-reference={inplace=false, type-reference=CPP/ConnectionContextItem_settings_DomainNameServers_VECTOR}
        settings_Gateway: type-reference={inplace=false, type-reference=String}
        settings_Proxy: type-reference={inplace=false, type-reference=String}
        ipv6_Settings_Interface: type-reference={inplace=false, type-reference=String}
        ipv6_Settings_Address: type-reference={inplace=false, type-reference=String}
        ipv6_Settings_PrefixLength: type-reference={inplace=false, type-reference=String}
        ipv6_Settings_DomainNameServers: type-reference={inplace=false, type-reference=CPP/ConnectionContextItem_ipv6_Settings_DomainNameServers_VECTOR}
        ipv6_Settings_Gateway: type-reference={inplace=false, type-reference=String}
        ivn_Settings_VLANID: type-reference={inplace=false, type-reference=String}
        ivn_Settings_Interface: type-reference={inplace=false, type-reference=String}
        ivn_Settings_Address: type-reference={inplace=false, type-reference=String}
        ivn_Settings_RemoteAddress: type-reference={inplace=false, type-reference=String}
        ivn_Settings_Netmask: type-reference={inplace=false, type-reference=String}
    ConnectionContextItem: category=STRUCTURE, type-emitter=TYPE_EMITTER_ARA
      namespaces:
        symbol props DCU
        symbol props Telephony
        symbol props EngineeringMode
      27 x cpp implementation data type element:
        contextIndex: type-reference={inplace=false, type-reference=CPP/ContextIndex}
        contextPath: type-reference={inplace=false, type-reference=String}
        status: type-reference={inplace=false, type-reference=CPP/ContextStatus}
        deactivateReason: type-reference={inplace=false, type-reference=CPP/DeactivateReason}
        accessPointName: type-reference={inplace=false, type-reference=String}
        type: type-reference={inplace=false, type-reference=String}
        username: type-reference={inplace=false, type-reference=String}
        password: type-reference={inplace=false, type-reference=String}
        protocol: type-reference={inplace=false, type-reference=String}
        name: type-reference={inplace=false, type-reference=String}
        settings_Interface: type-reference={inplace=false, type-reference=String}
        settings_Method: type-reference={inplace=false, type-reference=String}
        settings_Address: type-reference={inplace=false, type-reference=String}
        settings_Netmask: type-reference={inplace=false, type-reference=String}
        settings_DomainNameServers: type-reference={inplace=false, type-reference=CPP/ConnectionContextItem_settings_DomainNameServers_VECTOR}
        settings_Gateway: type-reference={inplace=false, type-reference=String}
        settings_Proxy: type-reference={inplace=false, type-reference=String}
        ipv6_Settings_Interface: type-reference={inplace=false, type-reference=String}
        ipv6_Settings_Address: type-reference={inplace=false, type-reference=String}
        ipv6_Settings_PrefixLength: type-reference={inplace=false, type-reference=String}
        ipv6_Settings_DomainNameServers: type-reference={inplace=false, type-reference=CPP/ConnectionContextItem_ipv6_Settings_DomainNameServers_VECTOR}
        ipv6_Settings_Gateway: type-reference={inplace=false, type-reference=String}
        ivn_Settings_VLANID: type-reference={inplace=false, type-reference=String}
        ivn_Settings_Interface: type-reference={inplace=false, type-reference=String}
        ivn_Settings_Address: type-reference={inplace=false, type-reference=String}
        ivn_Settings_RemoteAddress: type-reference={inplace=false, type-reference=String}
        ivn_Settings_Netmask: type-reference={inplace=false, type-reference=String}
    ConnectionContextItem: category=STRUCTURE, type-emitter=TYPE_EMITTER_ARA
      namespaces:
        symbol props DCU
        symbol props Telephony
        symbol props VoiceCallManager
      27 x cpp implementation data type element:
        contextIndex: type-reference={inplace=false, type-reference=CPP/ContextIndex}
        contextPath: type-reference={inplace=false, type-reference=String}
        status: type-reference={inplace=false, type-reference=CPP/ContextStatus}
        deactivateReason: type-reference={inplace=false, type-reference=CPP/DeactivateReason}
        accessPointName: type-reference={inplace=false, type-reference=String}
        type: type-reference={inplace=false, type-reference=String}
        username: type-reference={inplace=false, type-reference=String}
        password: type-reference={inplace=false, type-reference=String}
        protocol: type-reference={inplace=false, type-reference=String}
        name: type-reference={inplace=false, type-reference=String}
        settings_Interface: type-reference={inplace=false, type-reference=String}
        settings_Method: type-reference={inplace=false, type-reference=String}
        settings_Address: type-reference={inplace=false, type-reference=String}
        settings_Netmask: type-reference={inplace=false, type-reference=String}
        settings_DomainNameServers: type-reference={inplace=false, type-reference=CPP/ConnectionContextItem_settings_DomainNameServers_VECTOR}
        settings_Gateway: type-reference={inplace=false, type-reference=String}
        settings_Proxy: type-reference={inplace=false, type-reference=String}
        ipv6_Settings_Interface: type-reference={inplace=false, type-reference=String}
        ipv6_Settings_Address: type-reference={inplace=false, type-reference=String}
        ipv6_Settings_PrefixLength: type-reference={inplace=false, type-reference=String}
        ipv6_Settings_DomainNameServers: type-reference={inplace=false, type-reference=CPP/ConnectionContextItem_ipv6_Settings_DomainNameServers_VECTOR}
        ipv6_Settings_Gateway: type-reference={inplace=false, type-reference=String}
        ivn_Settings_VLANID: type-reference={inplace=false, type-reference=String}
        ivn_Settings_Interface: type-reference={inplace=false, type-reference=String}
        ivn_Settings_Address: type-reference={inplace=false, type-reference=String}
        ivn_Settings_RemoteAddress: type-reference={inplace=false, type-reference=String}
        ivn_Settings_Netmask: type-reference={inplace=false, type-reference=String}
    ConnectionContextItem: category=STRUCTURE, type-emitter=TYPE_EMITTER_ARA
      namespaces:
        symbol props DCU
        symbol props Telephony
        symbol props SimManager
      27 x cpp implementation data type element:
        contextIndex: type-reference={inplace=false, type-reference=CPP/ContextIndex}
        contextPath: type-reference={inplace=false, type-reference=String}
        status: type-reference={inplace=false, type-reference=CPP/ContextStatus}
        deactivateReason: type-reference={inplace=false, type-reference=CPP/DeactivateReason}
        accessPointName: type-reference={inplace=false, type-reference=String}
        type: type-reference={inplace=false, type-reference=String}
        username: type-reference={inplace=false, type-reference=String}
        password: type-reference={inplace=false, type-reference=String}
        protocol: type-reference={inplace=false, type-reference=String}
        name: type-reference={inplace=false, type-reference=String}
        settings_Interface: type-reference={inplace=false, type-reference=String}
        settings_Method: type-reference={inplace=false, type-reference=String}
        settings_Address: type-reference={inplace=false, type-reference=String}
        settings_Netmask: type-reference={inplace=false, type-reference=String}
        settings_DomainNameServers: type-reference={inplace=false, type-reference=CPP/ConnectionContextItem_settings_DomainNameServers_VECTOR}
        settings_Gateway: type-reference={inplace=false, type-reference=String}
        settings_Proxy: type-reference={inplace=false, type-reference=String}
        ipv6_Settings_Interface: type-reference={inplace=false, type-reference=String}
        ipv6_Settings_Address: type-reference={inplace=false, type-reference=String}
        ipv6_Settings_PrefixLength: type-reference={inplace=false, type-reference=String}
        ipv6_Settings_DomainNameServers: type-reference={inplace=false, type-reference=CPP/ConnectionContextItem_ipv6_Settings_DomainNameServers_VECTOR}
        ipv6_Settings_Gateway: type-reference={inplace=false, type-reference=String}
        ivn_Settings_VLANID: type-reference={inplace=false, type-reference=String}
        ivn_Settings_Interface: type-reference={inplace=false, type-reference=String}
        ivn_Settings_Address: type-reference={inplace=false, type-reference=String}
        ivn_Settings_RemoteAddress: type-reference={inplace=false, type-reference=String}
        ivn_Settings_Netmask: type-reference={inplace=false, type-reference=String}
    ConnectionContextItem: category=STRUCTURE, type-emitter=TYPE_EMITTER_ARA
      namespaces:
        symbol props DCU
        symbol props Telephony
        symbol props ConnectionContext
      27 x cpp implementation data type element:
        contextIndex: type-reference={inplace=false, type-reference=CPP/ContextIndex}
        contextPath: type-reference={inplace=false, type-reference=String}
        status: type-reference={inplace=false, type-reference=CPP/ContextStatus}
        deactivateReason: type-reference={inplace=false, type-reference=CPP/DeactivateReason}
        accessPointName: type-reference={inplace=false, type-reference=String}
        type: type-reference={inplace=false, type-reference=String}
        username: type-reference={inplace=false, type-reference=String}
        password: type-reference={inplace=false, type-reference=String}
        protocol: type-reference={inplace=false, type-reference=String}
        name: type-reference={inplace=false, type-reference=String}
        settings_Interface: type-reference={inplace=false, type-reference=String}
        settings_Method: type-reference={inplace=false, type-reference=String}
        settings_Address: type-reference={inplace=false, type-reference=String}
        settings_Netmask: type-reference={inplace=false, type-reference=String}
        settings_DomainNameServers: type-reference={inplace=false, type-reference=CPP/ConnectionContextItem_settings_DomainNameServers_VECTOR}
        settings_Gateway: type-reference={inplace=false, type-reference=String}
        settings_Proxy: type-reference={inplace=false, type-reference=String}
        ipv6_Settings_Interface: type-reference={inplace=false, type-reference=String}
        ipv6_Settings_Address: type-reference={inplace=false, type-reference=String}
        ipv6_Settings_PrefixLength: type-reference={inplace=false, type-reference=String}
        ipv6_Settings_DomainNameServers: type-reference={inplace=false, type-reference=CPP/ConnectionContextItem_ipv6_Settings_DomainNameServers_VECTOR}
        ipv6_Settings_Gateway: type-reference={inplace=false, type-reference=String}
        ivn_Settings_VLANID: type-reference={inplace=false, type-reference=String}
        ivn_Settings_Interface: type-reference={inplace=false, type-reference=String}
        ivn_Settings_Address: type-reference={inplace=false, type-reference=String}
        ivn_Settings_RemoteAddress: type-reference={inplace=false, type-reference=String}
        ivn_Settings_Netmask: type-reference={inplace=false, type-reference=String}
    ConnectionContextItem: category=STRUCTURE, type-emitter=TYPE_EMITTER_ARA
      namespaces:
        symbol props DCU
        symbol props Telephony
        symbol props ConnectionManager
      27 x cpp implementation data type element:
        contextIndex: type-reference={inplace=false, type-reference=CPP/ContextIndex}
        contextPath: type-reference={inplace=false, type-reference=String}
        status: type-reference={inplace=false, type-reference=CPP/ContextStatus}
        deactivateReason: type-reference={inplace=false, type-reference=CPP/DeactivateReason}
        accessPointName: type-reference={inplace=false, type-reference=String}
        type: type-reference={inplace=false, type-reference=String}
        username: type-reference={inplace=false, type-reference=String}
        password: type-reference={inplace=false, type-reference=String}
        protocol: type-reference={inplace=false, type-reference=String}
        name: type-reference={inplace=false, type-reference=String}
        settings_Interface: type-reference={inplace=false, type-reference=String}
        settings_Method: type-reference={inplace=false, type-reference=String}
        settings_Address: type-reference={inplace=false, type-reference=String}
        settings_Netmask: type-reference={inplace=false, type-reference=String}
        settings_DomainNameServers: type-reference={inplace=false, type-reference=CPP/ConnectionContextItem_settings_DomainNameServers_VECTOR}
        settings_Gateway: type-reference={inplace=false, type-reference=String}
        settings_Proxy: type-reference={inplace=false, type-reference=String}
        ipv6_Settings_Interface: type-reference={inplace=false, type-reference=String}
        ipv6_Settings_Address: type-reference={inplace=false, type-reference=String}
        ipv6_Settings_PrefixLength: type-reference={inplace=false, type-reference=String}
        ipv6_Settings_DomainNameServers: type-reference={inplace=false, type-reference=CPP/ConnectionContextItem_ipv6_Settings_DomainNameServers_VECTOR}
        ipv6_Settings_Gateway: type-reference={inplace=false, type-reference=String}
        ivn_Settings_VLANID: type-reference={inplace=false, type-reference=String}
        ivn_Settings_Interface: type-reference={inplace=false, type-reference=String}
        ivn_Settings_Address: type-reference={inplace=false, type-reference=String}
        ivn_Settings_RemoteAddress: type-reference={inplace=false, type-reference=String}
        ivn_Settings_Netmask: type-reference={inplace=false, type-reference=String}
    ConnectionContextItem: category=STRUCTURE, type-emitter=TYPE_EMITTER_ARA
      namespaces:
        symbol props DCU
        symbol props Telephony
        symbol props NetworkInformation
      27 x cpp implementation data type element:
        contextIndex: type-reference={inplace=false, type-reference=CPP/ContextIndex}
        contextPath: type-reference={inplace=false, type-reference=String}
        status: type-reference={inplace=false, type-reference=CPP/ContextStatus}
        deactivateReason: type-reference={inplace=false, type-reference=CPP/DeactivateReason}
        accessPointName: type-reference={inplace=false, type-reference=String}
        type: type-reference={inplace=false, type-reference=String}
        username: type-reference={inplace=false, type-reference=String}
        password: type-reference={inplace=false, type-reference=String}
        protocol: type-reference={inplace=false, type-reference=String}
        name: type-reference={inplace=false, type-reference=String}
        settings_Interface: type-reference={inplace=false, type-reference=String}
        settings_Method: type-reference={inplace=false, type-reference=String}
        settings_Address: type-reference={inplace=false, type-reference=String}
        settings_Netmask: type-reference={inplace=false, type-reference=String}
        settings_DomainNameServers: type-reference={inplace=false, type-reference=CPP/ConnectionContextItem_settings_DomainNameServers_VECTOR}
        settings_Gateway: type-reference={inplace=false, type-reference=String}
        settings_Proxy: type-reference={inplace=false, type-reference=String}
        ipv6_Settings_Interface: type-reference={inplace=false, type-reference=String}
        ipv6_Settings_Address: type-reference={inplace=false, type-reference=String}
        ipv6_Settings_PrefixLength: type-reference={inplace=false, type-reference=String}
        ipv6_Settings_DomainNameServers: type-reference={inplace=false, type-reference=CPP/ConnectionContextItem_ipv6_Settings_DomainNameServers_VECTOR}
        ipv6_Settings_Gateway: type-reference={inplace=false, type-reference=String}
        ivn_Settings_VLANID: type-reference={inplace=false, type-reference=String}
        ivn_Settings_Interface: type-reference={inplace=false, type-reference=String}
        ivn_Settings_Address: type-reference={inplace=false, type-reference=String}
        ivn_Settings_RemoteAddress: type-reference={inplace=false, type-reference=String}
        ivn_Settings_Netmask: type-reference={inplace=false, type-reference=String}
    ConnectionContextItem: category=STRUCTURE, type-emitter=TYPE_EMITTER_ARA
      namespaces:
        symbol props DCU
        symbol props Telephony
        symbol props ModemManager
      27 x cpp implementation data type element:
        contextIndex: type-reference={inplace=false, type-reference=CPP/ContextIndex}
        contextPath: type-reference={inplace=false, type-reference=String}
        status: type-reference={inplace=false, type-reference=CPP/ContextStatus}
        deactivateReason: type-reference={inplace=false, type-reference=CPP/DeactivateReason}
        accessPointName: type-reference={inplace=false, type-reference=String}
        type: type-reference={inplace=false, type-reference=String}
        username: type-reference={inplace=false, type-reference=String}
        password: type-reference={inplace=false, type-reference=String}
        protocol: type-reference={inplace=false, type-reference=String}
        name: type-reference={inplace=false, type-reference=String}
        settings_Interface: type-reference={inplace=false, type-reference=String}
        settings_Method: type-reference={inplace=false, type-reference=String}
        settings_Address: type-reference={inplace=false, type-reference=String}
        settings_Netmask: type-reference={inplace=false, type-reference=String}
        settings_DomainNameServers: type-reference={inplace=false, type-reference=CPP/ConnectionContextItem_settings_DomainNameServers_VECTOR}
        settings_Gateway: type-reference={inplace=false, type-reference=String}
        settings_Proxy: type-reference={inplace=false, type-reference=String}
        ipv6_Settings_Interface: type-reference={inplace=false, type-reference=String}
        ipv6_Settings_Address: type-reference={inplace=false, type-reference=String}
        ipv6_Settings_PrefixLength: type-reference={inplace=false, type-reference=String}
        ipv6_Settings_DomainNameServers: type-reference={inplace=false, type-reference=CPP/ConnectionContextItem_ipv6_Settings_DomainNameServers_VECTOR}
        ipv6_Settings_Gateway: type-reference={inplace=false, type-reference=String}
        ivn_Settings_VLANID: type-reference={inplace=false, type-reference=String}
        ivn_Settings_Interface: type-reference={inplace=false, type-reference=String}
        ivn_Settings_Address: type-reference={inplace=false, type-reference=String}
        ivn_Settings_RemoteAddress: type-reference={inplace=false, type-reference=String}
        ivn_Settings_Netmask: type-reference={inplace=false, type-reference=String}
    ConnectionContextItem_ipv6_Settings_DomainNameServers_VECTOR: category=VECTOR, cpp-template-argument=String, type-emitter=TYPE_EMITTER_ARA
      namespaces:
        symbol props DCU
        symbol props Telephony
        symbol props MessageManager
    ConnectionContextItem_ipv6_Settings_DomainNameServers_VECTOR: category=VECTOR, cpp-template-argument=String, type-emitter=TYPE_EMITTER_ARA
      namespaces:
        symbol props DCU
        symbol props Telephony
        symbol props EngineeringMode
    ConnectionContextItem_ipv6_Settings_DomainNameServers_VECTOR: category=VECTOR, cpp-template-argument=String, type-emitter=TYPE_EMITTER_ARA
      namespaces:
        symbol props DCU
        symbol props Telephony
        symbol props VoiceCallManager
    ConnectionContextItem_ipv6_Settings_DomainNameServers_VECTOR: category=VECTOR, cpp-template-argument=String, type-emitter=TYPE_EMITTER_ARA
      namespaces:
        symbol props DCU
        symbol props Telephony
        symbol props SimManager
    ConnectionContextItem_ipv6_Settings_DomainNameServers_VECTOR: category=VECTOR, cpp-template-argument=String, type-emitter=TYPE_EMITTER_ARA
      namespaces:
        symbol props DCU
        symbol props Telephony
        symbol props ConnectionContext
    ConnectionContextItem_ipv6_Settings_DomainNameServers_VECTOR: category=VECTOR, cpp-template-argument=String, type-emitter=TYPE_EMITTER_ARA
      namespaces:
        symbol props DCU
        symbol props Telephony
        symbol props ConnectionManager
    ConnectionContextItem_ipv6_Settings_DomainNameServers_VECTOR: category=VECTOR, cpp-template-argument=String, type-emitter=TYPE_EMITTER_ARA
      namespaces:
        symbol props DCU
        symbol props Telephony
        symbol props NetworkInformation
    ConnectionContextItem_ipv6_Settings_DomainNameServers_VECTOR: category=VECTOR, cpp-template-argument=String, type-emitter=TYPE_EMITTER_ARA
      namespaces:
        symbol props DCU
        symbol props Telephony
        symbol props ModemManager
    ConnectionContextItem_settings_DomainNameServers_VECTOR: category=VECTOR, cpp-template-argument=String, type-emitter=TYPE_EMITTER_ARA
      namespaces:
        symbol props DCU
        symbol props Telephony
        symbol props MessageManager
    ConnectionContextItem_settings_DomainNameServers_VECTOR: category=VECTOR, cpp-template-argument=String, type-emitter=TYPE_EMITTER_ARA
      namespaces:
        symbol props DCU
        symbol props Telephony
        symbol props EngineeringMode
    ConnectionContextItem_settings_DomainNameServers_VECTOR: category=VECTOR, cpp-template-argument=String, type-emitter=TYPE_EMITTER_ARA
      namespaces:
        symbol props DCU
        symbol props Telephony
        symbol props VoiceCallManager
    ConnectionContextItem_settings_DomainNameServers_VECTOR: category=VECTOR, cpp-template-argument=String, type-emitter=TYPE_EMITTER_ARA
      namespaces:
        symbol props DCU
        symbol props Telephony
        symbol props SimManager
    ConnectionContextItem_settings_DomainNameServers_VECTOR: category=VECTOR, cpp-template-argument=String, type-emitter=TYPE_EMITTER_ARA
      namespaces:
        symbol props DCU
        symbol props Telephony
        symbol props ConnectionContext
    ConnectionContextItem_settings_DomainNameServers_VECTOR: category=VECTOR, cpp-template-argument=String, type-emitter=TYPE_EMITTER_ARA
      namespaces:
        symbol props DCU
        symbol props Telephony
        symbol props ConnectionManager
    ConnectionContextItem_settings_DomainNameServers_VECTOR: category=VECTOR, cpp-template-argument=String, type-emitter=TYPE_EMITTER_ARA
      namespaces:
        symbol props DCU
        symbol props Telephony
        symbol props NetworkInformation
    ConnectionContextItem_settings_DomainNameServers_VECTOR: category=VECTOR, cpp-template-argument=String, type-emitter=TYPE_EMITTER_ARA
      namespaces:
        symbol props DCU
        symbol props Telephony
        symbol props ModemManager
    ConnectionStatus: compu {texttable}, range raw 0..2, type-emitter=TYPE_EMITTER_ARA, type-reference=uint32_t
      namespaces:
        symbol props Vehicle
        symbol props Vcc
        symbol props Policy
    ConnectionStatus: compu {texttable}, range raw 0..2, type-emitter=TYPE_EMITTER_ARA, type-reference=uint32_t
      namespaces:
        symbol props Vehicle
        symbol props Vcc
        symbol props Manager
    ConnectionStatus: compu {texttable}, range raw 0..2, type-emitter=TYPE_EMITTER_ARA, type-reference=uint32_t
      namespaces:
        symbol props CCU
        symbol props ExternalNetwork
        symbol props Manager2
    ConnectionStatusMap: category=ASSOCIATIVE_MAP, type-emitter=TYPE_EMITTER_ARA
      namespaces:
        symbol props Vehicle
        symbol props Vcc
        symbol props Policy
      template-arguments:
        category=ASSOC_MAP_KEY, template-type=uint64_t
        category=ASSOC_MAP_VALUE, template-type=CPP/ConnectionStatus
    Connectivity: compu {texttable}, range raw 0..1, type-emitter=TYPE_EMITTER_ARA, type-reference=uint32_t
      namespaces:
        symbol props Vehicle
        symbol props CIDS
        symbol props CIDSInfo
    Connectivity: compu {texttable}, range raw 0..1, type-emitter=TYPE_EMITTER_ARA, type-reference=uint32_t
      namespaces:
        symbol props Vehicle
        symbol props EIDS
        symbol props EIDSInfo
    ConnnectionContextStruct: category=STRUCTURE, type-emitter=TYPE_EMITTER_ARA
      namespaces:
        symbol props DCU
        symbol props Telephony
        symbol props ConnectionContext
      21 x cpp implementation data type element:
        active: type-reference={inplace=false, type-reference=bool}
        accessPointName: type-reference={inplace=false, type-reference=String}
        type: type-reference={inplace=false, type-reference=String}
        username: type-reference={inplace=false, type-reference=String}
        password: type-reference={inplace=false, type-reference=String}
        protocol: type-reference={inplace=false, type-reference=String}
        name: type-reference={inplace=false, type-reference=String}
        settings_Interface: type-reference={inplace=false, type-reference=String}
        settings_Method: type-reference={inplace=false, type-reference=String}
        settings_Address: type-reference={inplace=false, type-reference=String}
        settings_Netmask: type-reference={inplace=false, type-reference=String}
        settings_DomainNameServers: type-reference={inplace=false, type-reference=ConnnectionContextStruct_settings_DomainNameServers_VECTOR}
        settings_Gateway: type-reference={inplace=false, type-reference=String}
        settings_Proxy: type-reference={inplace=false, type-reference=String}
        ipv6_Settings_Interface: type-reference={inplace=false, type-reference=String}
        ipv6_Settings_Address: type-reference={inplace=false, type-reference=String}
        ipv6_Settings_PrefixLength: type-reference={inplace=false, type-reference=String}
        ipv6_Settings_DomainNameServers: type-reference={inplace=false, type-reference=ConnnectionContextStruct_ipv6_Settings_DomainNameServers_VECTOR}
        ipv6_Settings_Gateway: type-reference={inplace=false, type-reference=String}
        messageProxy: type-reference={inplace=false, type-reference=String}
        messageCenter: type-reference={inplace=false, type-reference=String}
    ConnnectionContextStruct_ipv6_Settings_DomainNameServers_VECTOR: category=VECTOR, cpp-template-argument=String, type-emitter=TYPE_EMITTER_ARA
      namespaces:
        symbol props DCU
        symbol props Telephony
        symbol props ConnectionContext
    ConnnectionContextStruct_settings_DomainNameServers_VECTOR: category=VECTOR, cpp-template-argument=String, type-emitter=TYPE_EMITTER_ARA
      namespaces:
        symbol props DCU
        symbol props Telephony
        symbol props ConnectionContext
    ContextAdded_EventData: category=STRUCTURE, type-emitter=TYPE_EMITTER_ARA
      namespaces:
        symbol props DCU
        symbol props Telephony
        symbol props ConnectionManager
      cpp implementation data type element contextPath: type-reference={inplace=false, type-reference=String}
      cpp implementation data type element item: type-reference={inplace=false, type-reference=CPP/ConnectionContextItem}
    ContextError: compu {texttable}, range raw 0..3, type-emitter=TYPE_EMITTER_ARA, type-reference=uint32_t
      namespaces:
        symbol props DCU
        symbol props Telephony
        symbol props MessageManager
    ContextError: compu {texttable}, range raw 0..3, type-emitter=TYPE_EMITTER_ARA, type-reference=uint32_t
      namespaces:
        symbol props DCU
        symbol props Telephony
        symbol props EngineeringMode
    ContextError: compu {texttable}, range raw 0..3, type-emitter=TYPE_EMITTER_ARA, type-reference=uint32_t
      namespaces:
        symbol props DCU
        symbol props Telephony
        symbol props VoiceCallManager
    ContextError: compu {texttable}, range raw 0..3, type-emitter=TYPE_EMITTER_ARA, type-reference=uint32_t
      namespaces:
        symbol props DCU
        symbol props Telephony
        symbol props SimManager
    ContextError: compu {texttable}, range raw 0..3, type-emitter=TYPE_EMITTER_ARA, type-reference=uint32_t
      namespaces:
        symbol props DCU
        symbol props Telephony
        symbol props ConnectionContext
    ContextError: compu {texttable}, range raw 0..3, type-emitter=TYPE_EMITTER_ARA, type-reference=uint32_t
      namespaces:
        symbol props CCU
        symbol props ExternalNetwork
        symbol props Manager2
    ContextError: compu {texttable}, range raw 0..3, type-emitter=TYPE_EMITTER_ARA, type-reference=uint32_t
      namespaces:
        symbol props DCU
        symbol props Telephony
        symbol props ConnectionManager
    ContextError: compu {texttable}, range raw 0..3, type-emitter=TYPE_EMITTER_ARA, type-reference=uint32_t
      namespaces:
        symbol props DCU
        symbol props Telephony
        symbol props NetworkInformation
    ContextError: compu {texttable}, range raw 0..3, type-emitter=TYPE_EMITTER_ARA, type-reference=uint32_t
      namespaces:
        symbol props DCU
        symbol props Telephony
        symbol props ModemManager
    ContextIndex: compu {texttable}, range raw 0..4, type-emitter=TYPE_EMITTER_ARA, type-reference=uint32_t
      namespaces:
        symbol props DCU
        symbol props Telephony
        symbol props MessageManager
    ContextIndex: compu {texttable}, range raw 0..4, type-emitter=TYPE_EMITTER_ARA, type-reference=uint32_t
      namespaces:
        symbol props DCU
        symbol props Telephony
        symbol props EngineeringMode
    ContextIndex: compu {texttable}, range raw 0..4, type-emitter=TYPE_EMITTER_ARA, type-reference=uint32_t
      namespaces:
        symbol props DCU
        symbol props Telephony
        symbol props VoiceCallManager
    ContextIndex: compu {texttable}, range raw 0..4, type-emitter=TYPE_EMITTER_ARA, type-reference=uint32_t
      namespaces:
        symbol props DCU
        symbol props Telephony
        symbol props SimManager
    ContextIndex: compu {texttable}, range raw 0..4, type-emitter=TYPE_EMITTER_ARA, type-reference=uint32_t
      namespaces:
        symbol props DCU
        symbol props Telephony
        symbol props ConnectionContext
    ContextIndex: compu {texttable}, range raw 0..4, type-emitter=TYPE_EMITTER_ARA, type-reference=uint32_t
      namespaces:
        symbol props DCU
        symbol props Telephony
        symbol props ConnectionManager
    ContextIndex: compu {texttable}, range raw 0..4, type-emitter=TYPE_EMITTER_ARA, type-reference=uint32_t
      namespaces:
        symbol props DCU
        symbol props Telephony
        symbol props NetworkInformation
    ContextIndex: compu {texttable}, range raw 0..4, type-emitter=TYPE_EMITTER_ARA, type-reference=uint32_t
      namespaces:
        symbol props DCU
        symbol props Telephony
        symbol props ModemManager
    ContextRemoved_EventData: category=STRUCTURE, type-emitter=TYPE_EMITTER_ARA
      namespaces:
        symbol props DCU
        symbol props Telephony
        symbol props ConnectionManager
      cpp implementation data type element contextPath: type-reference={inplace=false, type-reference=String}
    ContextStatus: compu {texttable}, range raw 0..2, type-emitter=TYPE_EMITTER_ARA, type-reference=uint32_t
      namespaces:
        symbol props DCU
        symbol props Telephony
        symbol props MessageManager
    ContextStatus: compu {texttable}, range raw 0..2, type-emitter=TYPE_EMITTER_ARA, type-reference=uint32_t
      namespaces:
        symbol props DCU
        symbol props Telephony
        symbol props EngineeringMode
    ContextStatus: compu {texttable}, range raw 0..2, type-emitter=TYPE_EMITTER_ARA, type-reference=uint32_t
      namespaces:
        symbol props DCU
        symbol props Telephony
        symbol props VoiceCallManager
    ContextStatus: compu {texttable}, range raw 0..2, type-emitter=TYPE_EMITTER_ARA, type-reference=uint32_t
      namespaces:
        symbol props DCU
        symbol props Telephony
        symbol props SimManager
    ContextStatus: compu {texttable}, range raw 0..2, type-emitter=TYPE_EMITTER_ARA, type-reference=uint32_t
      namespaces:
        symbol props DCU
        symbol props Telephony
        symbol props ConnectionContext
    ContextStatus: compu {texttable}, range raw 0..2, type-emitter=TYPE_EMITTER_ARA, type-reference=uint32_t
      namespaces:
        symbol props DCU
        symbol props Telephony
        symbol props ConnectionManager
    ContextStatus: compu {texttable}, range raw 0..2, type-emitter=TYPE_EMITTER_ARA, type-reference=uint32_t
      namespaces:
        symbol props DCU
        symbol props Telephony
        symbol props NetworkInformation
    ContextStatus: compu {texttable}, range raw 0..2, type-emitter=TYPE_EMITTER_ARA, type-reference=uint32_t
      namespaces:
        symbol props DCU
        symbol props Telephony
        symbol props ModemManager
    ControlType: compu {texttable}, range raw 0..3, type-emitter=TYPE_EMITTER_ARA, type-reference=uint32_t
      namespaces:
        symbol props Update
        symbol props USS
        symbol props UpdateStandard
    CrankInhibitStatus: compu {texttable}, range raw 0..3, type-emitter=TYPE_EMITTER_ARA, type-reference=uint32_t
      namespaces:
        symbol props Vehicle
        symbol props IPCHandler
        symbol props RoutingIPC
    CrankInhibitStatus: compu {texttable}, range raw 0..3, type-emitter=TYPE_EMITTER_ARA, type-reference=uint32_t
      namespaces:
        symbol props Vehicle
        symbol props ApSysMgr
        symbol props NetManager
    CustomHeaderMap: category=ASSOCIATIVE_MAP, template-arguments=[{category=ASSOC_MAP_KEY, template-type=String}, {category=ASSOC_MAP_VALUE, template-type=String}], type-emitter=TYPE_EMITTER_ARA
      namespaces:
        symbol props CCU
        symbol props Cloud
        symbol props Communicator
    DCanNetStatus: compu {texttable}, range raw 0..3, type-emitter=TYPE_EMITTER_ARA, type-reference=uint32_t
      namespaces:
        symbol props Vehicle
        symbol props IPCHandler
        symbol props RoutingIPC
    DCanNetStatus: compu {texttable}, range raw 0..3, type-emitter=TYPE_EMITTER_ARA, type-reference=uint32_t
      namespaces:
        symbol props Vehicle
        symbol props ApSysMgr
        symbol props NetManager
    DEVInfo_VECTOR: category=VECTOR, cpp-template-argument=CPP/EventInfo, type-emitter=TYPE_EMITTER_ARA
      namespaces:
        symbol props BltnCam
        symbol props DrivingEvent
        symbol props Manager
    DOP: category=STRUCTURE, type-emitter=TYPE_EMITTER_ARA
      namespaces:
        symbol props Info
        symbol props Location
        symbol props GNSS
      cpp implementation data type element pdop: type-reference={inplace=false, type-reference=uint16_t}  # Unit : 2^(-8)
      cpp implementation data type element hdop: type-reference={inplace=false, type-reference=uint16_t}  # Unit : 2^(-8)
      cpp implementation data type element vdop: type-reference={inplace=false, type-reference=uint16_t}  # Unit : 2^(-8)
    DTCStatusType: compu {texttable}, range raw 0..3, type-emitter=TYPE_EMITTER_ARA, type-reference=uint32_t
      namespaces:
        symbol props Vehicle
        symbol props SDE
        symbol props SelfDiagnosis
    DTEInfo: category=STRUCTURE, type-emitter=TYPE_EMITTER_ARA
      namespaces:
        symbol props Info
        symbol props Cluster
        symbol props InformationProvider
      cpp implementation data type element dte: type-reference={inplace=false, type-reference=float}
      cpp implementation data type element distunit: type-reference={inplace=false, type-reference=DistanceUnit}
    DTEStrInfo: category=STRUCTURE, type-emitter=TYPE_EMITTER_ARA
      namespaces:
        symbol props Info
        symbol props Cluster
        symbol props InformationProvider
      cpp implementation data type element dteStr: type-reference={inplace=false, type-reference=String}
      cpp implementation data type element distunit: type-reference={inplace=false, type-reference=DistanceUnit}
    DTMFError: compu {texttable}, range raw 0..5, type-emitter=TYPE_EMITTER_ARA, type-reference=uint32_t
      namespaces:
        symbol props DCU
        symbol props Telephony
        symbol props VoiceCallManager
    Data: category=STRUCTURE, type-emitter=TYPE_EMITTER_ARA
      namespaces:
        symbol props Vehicle
        symbol props Vcc
        symbol props Policy
      75 x cpp implementation data type element:
        fw_accept_packets: type-reference={inplace=false, type-reference=uint64_t}
        fw_accept_bytes: type-reference={inplace=false, type-reference=uint64_t}
        fw_drop_packets: type-reference={inplace=false, type-reference=uint64_t}
        fw_drop_bytes: type-reference={inplace=false, type-reference=uint64_t}
        apn0_tx_packets: type-reference={inplace=false, type-reference=uint64_t}
        apn0_tx_bytes: type-reference={inplace=false, type-reference=uint64_t}
        apn0_rx_packets: type-reference={inplace=false, type-reference=uint64_t}
        apn0_rx_bytes: type-reference={inplace=false, type-reference=uint64_t}
        apn1_tx_packets: type-reference={inplace=false, type-reference=uint64_t}
        apn1_tx_bytes: type-reference={inplace=false, type-reference=uint64_t}
        apn1_rx_packets: type-reference={inplace=false, type-reference=uint64_t}
        apn1_rx_bytes: type-reference={inplace=false, type-reference=uint64_t}
        apn2_tx_packets: type-reference={inplace=false, type-reference=uint64_t}
        apn2_tx_bytes: type-reference={inplace=false, type-reference=uint64_t}
        apn2_rx_packets: type-reference={inplace=false, type-reference=uint64_t}
        apn2_rx_bytes: type-reference={inplace=false, type-reference=uint64_t}
        apn3_tx_packets: type-reference={inplace=false, type-reference=uint64_t}
        apn3_tx_bytes: type-reference={inplace=false, type-reference=uint64_t}
        apn3_rx_packets: type-reference={inplace=false, type-reference=uint64_t}
        apn3_rx_bytes: type-reference={inplace=false, type-reference=uint64_t}
        apn4_tx_packets: type-reference={inplace=false, type-reference=uint64_t}
        apn4_tx_bytes: type-reference={inplace=false, type-reference=uint64_t}
        apn4_rx_packets: type-reference={inplace=false, type-reference=uint64_t}
        apn4_rx_bytes: type-reference={inplace=false, type-reference=uint64_t}
        apn5_tx_packets: type-reference={inplace=false, type-reference=uint64_t}
        apn5_tx_bytes: type-reference={inplace=false, type-reference=uint64_t}
        apn5_rx_packets: type-reference={inplace=false, type-reference=uint64_t}
        apn5_rx_bytes: type-reference={inplace=false, type-reference=uint64_t}
        sg_default_tx_packets: type-reference={inplace=false, type-reference=uint64_t}
        sg_default_tx_bytes: type-reference={inplace=false, type-reference=uint64_t}
        sg_default_rx_packets: type-reference={inplace=false, type-reference=uint64_t}
        sg_default_rx_bytes: type-reference={inplace=false, type-reference=uint64_t}
        sg_ccs_tx_packets: type-reference={inplace=false, type-reference=uint64_t}
        sg_ccs_tx_bytes: type-reference={inplace=false, type-reference=uint64_t}
        sg_ccs_rx_packets: type-reference={inplace=false, type-reference=uint64_t}
        sg_ccs_rx_bytes: type-reference={inplace=false, type-reference=uint64_t}
        sg_fota_tx_packets: type-reference={inplace=false, type-reference=uint64_t}
        sg_fota_tx_bytes: type-reference={inplace=false, type-reference=uint64_t}
        sg_fota_rx_packets: type-reference={inplace=false, type-reference=uint64_t}
        sg_fota_rx_bytes: type-reference={inplace=false, type-reference=uint64_t}
        sg_userpaid_tx_packets: type-reference={inplace=false, type-reference=uint64_t}
        sg_userpaid_tx_bytes: type-reference={inplace=false, type-reference=uint64_t}
        sg_userpaid_rx_packets: type-reference={inplace=false, type-reference=uint64_t}
        sg_userpaid_rx_bytes: type-reference={inplace=false, type-reference=uint64_t}
        sg_oempaid_tx_packets: type-reference={inplace=false, type-reference=uint64_t}
        sg_oempaid_tx_bytes: type-reference={inplace=false, type-reference=uint64_t}
        sg_oempaid_rx_packets: type-reference={inplace=false, type-reference=uint64_t}
        sg_oempaid_rx_bytes: type-reference={inplace=false, type-reference=uint64_t}
        sg_vcrm_tx_packets: type-reference={inplace=false, type-reference=uint64_t}
        sg_vcrm_tx_bytes: type-reference={inplace=false, type-reference=uint64_t}
        sg_vcrm_rx_packets: type-reference={inplace=false, type-reference=uint64_t}
        sg_vcrm_rx_bytes: type-reference={inplace=false, type-reference=uint64_t}
        sg_canids_tx_packets: type-reference={inplace=false, type-reference=uint64_t}
        sg_canids_tx_bytes: type-reference={inplace=false, type-reference=uint64_t}
        sg_canids_rx_packets: type-reference={inplace=false, type-reference=uint64_t}
        sg_canids_rx_bytes: type-reference={inplace=false, type-reference=uint64_t}
        sg_streaming_standard_tx_packets: type-reference={inplace=false, type-reference=uint64_t}
        sg_streaming_standard_tx_bytes: type-reference={inplace=false, type-reference=uint64_t}
        sg_streaming_standard_rx_packets: type-reference={inplace=false, type-reference=uint64_t}
        sg_streaming_standard_rx_bytes: type-reference={inplace=false, type-reference=uint64_t}
        sg_streaming_premium_tx_packets: type-reference={inplace=false, type-reference=uint64_t}
        sg_streaming_premium_tx_bytes: type-reference={inplace=false, type-reference=uint64_t}
        sg_streaming_premium_rx_packets: type-reference={inplace=false, type-reference=uint64_t}
        sg_streaming_premium_rx_bytes: type-reference={inplace=false, type-reference=uint64_t}
        sg_navi_vr_tx_packets: type-reference={inplace=false, type-reference=uint64_t}
        sg_navi_vr_tx_bytes: type-reference={inplace=false, type-reference=uint64_t}
        sg_navi_vr_rx_packets: type-reference={inplace=false, type-reference=uint64_t}
        sg_navi_vr_rx_bytes: type-reference={inplace=false, type-reference=uint64_t}
        sg_pbv_tx_packets: type-reference={inplace=false, type-reference=uint64_t}
        sg_pbv_tx_bytes: type-reference={inplace=false, type-reference=uint64_t}
        sg_pbv_rx_packets: type-reference={inplace=false, type-reference=uint64_t}
        sg_pbv_rx_bytes: type-reference={inplace=false, type-reference=uint64_t}
        svcGroup: type-reference={inplace=false, type-reference=CPP/GroupTypes}
        ipv4_address: type-reference={inplace=false, type-reference=String}
        ipv6_address: type-reference={inplace=false, type-reference=String}
    DataPlanProducts_VECTOR: category=VECTOR, cpp-template-argument=ProductItem, type-emitter=TYPE_EMITTER_ARA
      namespaces:
        symbol props Info
        symbol props Cloud
        symbol props ProvisioningTable
    DcuSystemTime: category=STRUCTURE, type-emitter=TYPE_EMITTER_ARA
      namespaces:
        symbol props Vehicle
        symbol props IPCHandler
        symbol props RoutingIPC
      8 x cpp implementation data type element:
        sec: type-reference={inplace=false, type-reference=int16_t}
        min: type-reference={inplace=false, type-reference=int16_t}
        hour: type-reference={inplace=false, type-reference=int16_t}
        mday: type-reference={inplace=false, type-reference=int16_t}
        mon: type-reference={inplace=false, type-reference=int16_t}
        year: type-reference={inplace=false, type-reference=int16_t}
        dst: type-reference={inplace=false, type-reference=int16_t}
        valid: type-reference={inplace=false, type-reference=bool}
    DeactivateReason: compu {texttable}, range raw 0..12, type-emitter=TYPE_EMITTER_ARA, type-reference=uint32_t
      namespaces:
        symbol props DCU
        symbol props Telephony
        symbol props MessageManager
    DeactivateReason: compu {texttable}, range raw 0..12, type-emitter=TYPE_EMITTER_ARA, type-reference=uint32_t
      namespaces:
        symbol props DCU
        symbol props Telephony
        symbol props EngineeringMode
    DeactivateReason: compu {texttable}, range raw 0..12, type-emitter=TYPE_EMITTER_ARA, type-reference=uint32_t
      namespaces:
        symbol props DCU
        symbol props Telephony
        symbol props VoiceCallManager
    DeactivateReason: compu {texttable}, range raw 0..12, type-emitter=TYPE_EMITTER_ARA, type-reference=uint32_t
      namespaces:
        symbol props DCU
        symbol props Telephony
        symbol props SimManager
    DeactivateReason: compu {texttable}, range raw 0..12, type-emitter=TYPE_EMITTER_ARA, type-reference=uint32_t
      namespaces:
        symbol props DCU
        symbol props Telephony
        symbol props ConnectionContext
    DeactivateReason: compu {texttable}, range raw 0..12, type-emitter=TYPE_EMITTER_ARA, type-reference=uint32_t
      namespaces:
        symbol props DCU
        symbol props Telephony
        symbol props ConnectionManager
    DeactivateReason: compu {texttable}, range raw 0..12, type-emitter=TYPE_EMITTER_ARA, type-reference=uint32_t
      namespaces:
        symbol props DCU
        symbol props Telephony
        symbol props NetworkInformation
    DeactivateReason: compu {texttable}, range raw 0..12, type-emitter=TYPE_EMITTER_ARA, type-reference=uint32_t
      namespaces:
        symbol props DCU
        symbol props Telephony
        symbol props ModemManager
    DiagHandleStatus: category=ASSOCIATIVE_MAP, type-emitter=TYPE_EMITTER_ARA
      namespaces:
        symbol props Vehicle
        symbol props DiagMgr
        symbol props RoutingDiag
      template-arguments:
        category=ASSOC_MAP_KEY, template-type=String
        category=ASSOC_MAP_VALUE, template-type=UInt32_vector
    DiagItem: category=STRUCTURE, type-emitter=TYPE_EMITTER_ARA
      namespaces:
        symbol props CCU
        symbol props Vehicle
        symbol props DiagnosticRouting
      cpp implementation data type element tid: type-reference={inplace=false, type-reference=uint32_t}  # Transaction ID
      cpp implementation data type element result: type-reference={inplace=false, type-reference=DiagnosisResult}  # DiagnosisResult
      cpp implementation data type element reqItem: type-reference={inplace=false, type-reference=DiagReqItem}  # Diagnosis item object
    DiagReqItem: category=STRUCTURE, type-emitter=TYPE_EMITTER_ARA
      namespaces:
        symbol props CCU
        symbol props Vehicle
        symbol props DiagnosticRouting
      4 x cpp implementation data type element:
        ecu_ID: type-reference={inplace=false, type-reference=uint32_t}
        payload_length: type-reference={inplace=false, type-reference=uint32_t}
        payload: type-reference={inplace=false, type-reference=DiagReqItem_payload_VECTOR}
        requestTimeout: type-reference={inplace=false, type-reference=uint32_t}  # timeout millisecond,
    DiagReqItem_payload_VECTOR: category=VECTOR, cpp-template-argument=uint8_t, type-emitter=TYPE_EMITTER_ARA
      namespaces:
        symbol props CCU
        symbol props Vehicle
        symbol props DiagnosticRouting
    DiagResItem: category=STRUCTURE, type-emitter=TYPE_EMITTER_ARA
      namespaces:
        symbol props CCU
        symbol props Vehicle
        symbol props DiagnosticRouting
      cpp implementation data type element ecu_ID: type-reference={inplace=false, type-reference=uint32_t}
      cpp implementation data type element payload_length: type-reference={inplace=false, type-reference=uint32_t}
      cpp implementation data type element payload: type-reference={inplace=false, type-reference=DiagResItem_payload_VECTOR}
    DiagResItem_payload_VECTOR: category=VECTOR, cpp-template-argument=uint8_t, type-emitter=TYPE_EMITTER_ARA
      namespaces:
        symbol props CCU
        symbol props Vehicle
        symbol props DiagnosticRouting
    DiagResponse: category=STRUCTURE, type-emitter=TYPE_EMITTER_ARA
      namespaces:
        symbol props Vehicle
        symbol props DiagMgr
        symbol props RoutingDiag
      cpp implementation data type element diagClientID: type-reference={inplace=false, type-reference=String}
      cpp implementation data type element diagTargetID: type-reference={inplace=false, type-reference=uint32_t}
      cpp implementation data type element responseData: type-reference={inplace=false, type-reference=ByteArray}
    DiagResponseResultType: compu {texttable}, range raw 0..8, type-emitter=TYPE_EMITTER_ARA, type-reference=uint32_t
      namespaces:
        symbol props Vehicle
        symbol props DiagMgr
        symbol props RoutingDiag
    DiagResponseType: compu {texttable}, range raw 0..4, type-emitter=TYPE_EMITTER_ARA, type-reference=uint32_t
      namespaces:
        symbol props Vehicle
        symbol props NSD
        symbol props NonSleep
    DiagResponseType: compu {texttable}, range raw 0..4, type-emitter=TYPE_EMITTER_ARA, type-reference=uint32_t
      namespaces:
        symbol props Update
        symbol props USS
        symbol props UpdateStandard
    DiagResponseType: compu {texttable}, range raw 0..4, type-emitter=TYPE_EMITTER_ARA, type-reference=uint32_t
      namespaces:
        symbol props Vehicle
        symbol props SDE
        symbol props SelfDiagnosis
    DiagResponseUpdated_EventData: category=STRUCTURE, type-emitter=TYPE_EMITTER_ARA
      namespaces:
        symbol props Vehicle
        symbol props DiagMgr
        symbol props RoutingDiag
      cpp implementation data type element diagResult: type-reference={inplace=false, type-reference=DiagResponseResultType}
      cpp implementation data type element diagResponse: type-reference={inplace=false, type-reference=DiagResponse}
    DiagResultType: compu {texttable}, range raw 0..5, type-emitter=TYPE_EMITTER_ARA, type-reference=uint32_t
      namespaces:
        symbol props Vehicle
        symbol props DiagMgr
        symbol props RoutingDiag
    DiagServiceType: compu {texttable}, range raw 20..61, type-emitter=TYPE_EMITTER_ARA, type-reference=uint32_t
      namespaces:
        symbol props Vehicle
        symbol props SDE
        symbol props SelfDiagnosis
    DiagSessionType: compu {texttable}, range raw 1..3, type-emitter=TYPE_EMITTER_ARA, type-reference=uint32_t
      namespaces:
        symbol props Update
        symbol props USS
        symbol props UpdateStandard
    DiagSessionType: compu {texttable}, range raw 1..3, type-emitter=TYPE_EMITTER_ARA, type-reference=uint32_t
      namespaces:
        symbol props Vehicle
        symbol props FlashingAdaptor
        symbol props PackageManagement
    DiagSessionType: compu {texttable}, range raw 1..3, type-emitter=TYPE_EMITTER_ARA, type-reference=uint32_t
      namespaces:
        symbol props Vehicle
        symbol props SDE
        symbol props SelfDiagnosis
    DiagSystemStatus: compu {texttable}, range raw 0..2, type-emitter=TYPE_EMITTER_ARA, type-reference=uint32_t
      namespaces:
        symbol props CCU
        symbol props Vehicle
        symbol props DiagnosticRouting
    DiagnosisMsgInfo: category=STRUCTURE, type-emitter=TYPE_EMITTER_ARA
      namespaces:
        symbol props Vehicle
        symbol props VSUA
        symbol props UdsReprogram
      cpp implementation data type element diagClientID: type-reference={inplace=false, type-reference=String}
      cpp implementation data type element diagTargetID: type-reference={inplace=false, type-reference=uint32_t}
      cpp implementation data type element diagMsg: type-reference={inplace=false, type-reference=ByteArray}
    DiagnosisQueue_VECTOR: category=VECTOR, cpp-template-argument=DiagItem, type-emitter=TYPE_EMITTER_ARA
      namespaces:
        symbol props CCU
        symbol props Vehicle
        symbol props DiagnosticRouting
    DiagnosisResult: compu {texttable}, range raw 0..11, type-emitter=TYPE_EMITTER_ARA, type-reference=uint32_t
      namespaces:
        symbol props CCU
        symbol props Vehicle
        symbol props DiagnosticRouting
    DiagnosisServices: compu {texttable}, range raw 0..7, type-emitter=TYPE_EMITTER_ARA, type-reference=uint32_t
      namespaces:
        symbol props CCU
        symbol props Vehicle
        symbol props DiagnosticRouting
    DiagnosisStateChanged_EventData: category=STRUCTURE, type-emitter=TYPE_EMITTER_ARA
      namespaces:
        symbol props CCU
        symbol props Vehicle
        symbol props DiagnosticRouting
      cpp implementation data type element tid: type-reference={inplace=false, type-reference=uint32_t}
      cpp implementation data type element result: type-reference={inplace=false, type-reference=DiagnosisResult}
      cpp implementation data type element res: type-reference={inplace=false, type-reference=DiagResItem}
    DiagnosticError: compu {texttable}, range raw 0..3, type-emitter=TYPE_EMITTER_ARA, type-reference=uint32_t
      namespaces:
        symbol props DCU
        symbol props System
        symbol props Variation
    DiagnosticError: compu {texttable}, range raw 0..3, type-emitter=TYPE_EMITTER_ARA, type-reference=uint32_t
      namespaces:
        symbol props DCU
        symbol props System
        symbol props Time
    DiagnosticError: compu {texttable}, range raw 0..3, type-emitter=TYPE_EMITTER_ARA, type-reference=uint32_t
      namespaces:
        symbol props DCU
        symbol props System
        symbol props PowerManagement
    DiagnosticError: compu {texttable}, range raw 0..3, type-emitter=TYPE_EMITTER_ARA, type-reference=uint32_t
      namespaces:
        symbol props CCU
        symbol props System
        symbol props EngineeringMode
    DistanceInfo: category=STRUCTURE, type-emitter=TYPE_EMITTER_ARA
      namespaces:
        symbol props Info
        symbol props Cluster
        symbol props InformationProvider
      cpp implementation data type element type: type-reference={inplace=false, type-reference=String}
      cpp implementation data type element distance: type-reference={inplace=false, type-reference=float}
      cpp implementation data type element unit: type-reference={inplace=false, type-reference=DistanceUnit}
    DistanceStrInfo: category=STRUCTURE, type-emitter=TYPE_EMITTER_ARA
      namespaces:
        symbol props Info
        symbol props Cluster
        symbol props InformationProvider
      cpp implementation data type element type: type-reference={inplace=false, type-reference=String}
      cpp implementation data type element distanceStr: type-reference={inplace=false, type-reference=String}
      cpp implementation data type element unit: type-reference={inplace=false, type-reference=String}
    DistanceUnit: compu {texttable}, range raw 0..1, type-emitter=TYPE_EMITTER_ARA, type-reference=uint32_t
      namespaces:
        symbol props Info
        symbol props Cluster
        symbol props InformationProvider
    DrivingModeInfo: category=STRUCTURE, type-emitter=TYPE_EMITTER_ARA
      namespaces:
        symbol props Info
        symbol props Cluster
        symbol props InformationProvider
      cpp implementation data type element mode: type-reference={inplace=false, type-reference=String}
      cpp implementation data type element selected: type-reference={inplace=false, type-reference=bool}
    DrivingModes_VECTOR: category=VECTOR, cpp-template-argument=DrivingModeInfo, type-emitter=TYPE_EMITTER_ARA
      namespaces:
        symbol props Info
        symbol props Cluster
        symbol props InformationProvider
    DualType: compu {texttable}, range raw 0..1, type-emitter=TYPE_EMITTER_ARA, type-reference=uint32_t
      namespaces:
        symbol props Vehicle
        symbol props UpdateMaster
        symbol props PackageManagement
    ECallSignal_R: compu {texttable}, range raw 0..6, type-emitter=TYPE_EMITTER_ARA, type-reference=uint32_t
      namespaces:
        symbol props CCU
        symbol props Vehicle
        symbol props S2S
    ECallStatus: compu {texttable}, range raw 0..3, type-emitter=TYPE_EMITTER_ARA, type-reference=uint32_t
      namespaces:
        symbol props DCU
        symbol props Telephony
        symbol props ModemManager
    ECall_R: category=STRUCTURE, type-emitter=TYPE_EMITTER_ARA
      namespaces:
        symbol props CCU
        symbol props Vehicle
        symbol props S2S
      cpp implementation data type element signalItem: type-reference={inplace=false, type-reference=ECallSignal_R}
      cpp implementation data type element signalValue: type-reference={inplace=false, type-reference=uint32_t}
    EIDSLogRetrieve_EventData: category=STRUCTURE, type-emitter=TYPE_EMITTER_ARA
      namespaces:
        symbol props Vehicle
        symbol props DPM
        symbol props Policy
      cpp implementation data type element newVersion: type-reference={inplace=false, type-reference=uint32_t}
    EIDSPolicyDownloaded_EventData: category=STRUCTURE, type-emitter=TYPE_EMITTER_ARA
      namespaces:
        symbol props Vehicle
        symbol props DPM
        symbol props Policy
      cpp implementation data type element newVersion: type-reference={inplace=false, type-reference=uint32_t}
    EcuId: compu {texttable}, range raw 0..127, type-emitter=TYPE_EMITTER_ARA, type-reference=uint32_t
      namespaces:
        symbol props Vehicle
        symbol props EthNM
        symbol props NM
    EcuStatus: category=STRUCTURE, type-emitter=TYPE_EMITTER_ARA
      namespaces:
        symbol props Vehicle
        symbol props EthNM
        symbol props NM
      cpp implementation data type element ecuIds: type-reference={inplace=false, type-reference=EcuStatus_ecuIds_VECTOR}
      cpp implementation data type element error: type-reference={inplace=false, type-reference=CPP/Error}
    EcuStatus_ecuIds_VECTOR: category=VECTOR, cpp-template-argument=EcuId, type-emitter=TYPE_EMITTER_ARA
      namespaces:
        symbol props Vehicle
        symbol props EthNM
        symbol props NM
    EidsAppInfo: category=STRUCTURE, type-emitter=TYPE_EMITTER_ARA
      namespaces:
        symbol props Vehicle
        symbol props EIDS
        symbol props EIDSInfo
      4 x cpp implementation data type element:
        vendorCode: type-reference={inplace=false, type-reference=String}
        connectivity: type-reference={inplace=false, type-reference=CPP/Connectivity}
        region: type-reference={inplace=false, type-reference=uint8_t}
        timeMode: type-reference={inplace=false, type-reference=CPP/TimeMode}
    EidsAppState: category=STRUCTURE, type-emitter=TYPE_EMITTER_ARA
      namespaces:
        symbol props Vehicle
        symbol props EIDS
        symbol props EIDSInfo
      5 x cpp implementation data type element, all with type-reference={inplace=false, type-reference=CPP/ModuleState}:
        appState
        engineState
        ruleState
        loggerState
        senderState
    EidsVersionInfo: category=STRUCTURE, type-emitter=TYPE_EMITTER_ARA
      namespaces:
        symbol props Vehicle
        symbol props EIDS
        symbol props EIDSInfo
      5 x cpp implementation data type element, all with type-reference={inplace=false, type-reference=String}:
        eidsVersion
        ruleVersion
        apVersion
        ethDbVersion
        policyVersion
    EndpointConfig: category=STRUCTURE, type-emitter=TYPE_EMITTER_ARA
      namespaces:
        symbol props Vehicle
        symbol props Vcc
        symbol props Manager
      6 x cpp implementation data type element:
        grouptype: type-reference={inplace=false, type-reference=CPP/GroupTypes}
        ipv4_address: type-reference={inplace=false, type-reference=String}
        ipv6_address: type-reference={inplace=false, type-reference=String}
        nameservers: type-reference={inplace=false, type-reference=String}
        mac_address: type-reference={inplace=false, type-reference=String}
        iptype: type-reference={inplace=false, type-reference=CPP/ProtocolTypes}
    EndpointConfigInformation_VECTOR: category=VECTOR, cpp-template-argument=EndpointConfig, type-emitter=TYPE_EMITTER_ARA
      namespaces:
        symbol props Vehicle
        symbol props Vcc
        symbol props Manager
    EndpointConfiguration: category=STRUCTURE, type-emitter=TYPE_EMITTER_ARA
      namespaces:
        symbol props CCU
        symbol props ExternalNetwork
        symbol props Manager2
      11 x cpp implementation data type element:
        endpointtype: type-reference={inplace=false, type-reference=String}
        vlan_id: type-reference={inplace=false, type-reference=String}
        ipv4_address: type-reference={inplace=false, type-reference=EndpointConfiguration_ipv4_address_VECTOR}
        ipv4_netmask: type-reference={inplace=false, type-reference=String}
        ipv4_gateway: type-reference={inplace=false, type-reference=String}
        ipv6_address: type-reference={inplace=false, type-reference=EndpointConfiguration_ipv6_address_VECTOR}
        ipv6_prefixlength: type-reference={inplace=false, type-reference=String}
        ipv6_gateway: type-reference={inplace=false, type-reference=String}
        nameservers: type-reference={inplace=false, type-reference=EndpointConfiguration_nameservers_VECTOR}
        ipv4_arl_tables: type-reference={inplace=false, type-reference=EndpointConfiguration_ipv4_arl_tables_VECTOR}
        ipv6_arl_tables: type-reference={inplace=false, type-reference=EndpointConfiguration_ipv6_arl_tables_VECTOR}
    EndpointConfiguration_ipv4_address_VECTOR: category=VECTOR, cpp-template-argument=String, type-emitter=TYPE_EMITTER_ARA
      namespaces:
        symbol props CCU
        symbol props ExternalNetwork
        symbol props Manager2
    EndpointConfiguration_ipv4_arl_tables_VECTOR: category=VECTOR, cpp-template-argument=ARLTableItem, type-emitter=TYPE_EMITTER_ARA
      namespaces:
        symbol props CCU
        symbol props ExternalNetwork
        symbol props Manager2
    EndpointConfiguration_ipv6_address_VECTOR: category=VECTOR, cpp-template-argument=String, type-emitter=TYPE_EMITTER_ARA
      namespaces:
        symbol props CCU
        symbol props ExternalNetwork
        symbol props Manager2
    EndpointConfiguration_ipv6_arl_tables_VECTOR: category=VECTOR, cpp-template-argument=ARLTableItem, type-emitter=TYPE_EMITTER_ARA
      namespaces:
        symbol props CCU
        symbol props ExternalNetwork
        symbol props Manager2
    EndpointConfiguration_nameservers_VECTOR: category=VECTOR, cpp-template-argument=String, type-emitter=TYPE_EMITTER_ARA
      namespaces:
        symbol props CCU
        symbol props ExternalNetwork
        symbol props Manager2
    EndpointType: compu {texttable}, range raw 0..2, type-emitter=TYPE_EMITTER_ARA, type-reference=uint32_t
      namespaces:
        symbol props Info
        symbol props System
        symbol props Variant
    EndpointType: compu {texttable}, range raw 0..2, type-emitter=TYPE_EMITTER_ARA, type-reference=uint32_t
      namespaces:
        symbol props Info
        symbol props System
        symbol props EngineeringMode
    EndpointType: compu {texttable}, range raw 0..2, type-emitter=TYPE_EMITTER_ARA, type-reference=uint32_t
      namespaces:
        symbol props Info
        symbol props System
        symbol props Time
    Environments: compu {texttable}, range raw 0..3, type-emitter=TYPE_EMITTER_ARA, type-reference=uint32_t
      namespaces:
        symbol props Vehicle
        symbol props Telemanager
        symbol props Provisioning
    EpochTime: category=STRUCTURE, type-emitter=TYPE_EMITTER_ARA
      namespaces:
        symbol props Vehicle
        symbol props ApSysMgr
        symbol props TimeManager
      cpp implementation data type element utcTime: type-reference={inplace=false, type-reference=uint64_t}
      cpp implementation data type element mode: type-reference={inplace=false, type-reference=CPP/TimeMode}
      cpp implementation data type element utcOffset: type-reference={inplace=false, type-reference=int16_t}
    ErrCode: compu {texttable}, range raw 0..7, type-emitter=TYPE_EMITTER_ARA, type-reference=uint32_t
      namespaces:
        symbol props Vehicle
        symbol props Security
        symbol props EcDec
    ErrCode: compu {texttable}, range raw 0..7, type-emitter=TYPE_EMITTER_ARA, type-reference=uint32_t
      namespaces:
        symbol props Vehicle
        symbol props Security
        symbol props IVPA
    ErrCode: compu {texttable}, range raw 0..7, type-emitter=TYPE_EMITTER_ARA, type-reference=uint32_t
      namespaces:
        symbol props Vehicle
        symbol props Security
        symbol props MassProc
    Error: compu {texttable}, range raw 0..22, type-emitter=TYPE_EMITTER_ARA, type-reference=uint32_t
      namespaces:
        symbol props Vehicle
        symbol props ApSysMgr
        symbol props SysInfoManager
    Error: compu {texttable}, range raw 0..22, type-emitter=TYPE_EMITTER_ARA, type-reference=uint32_t
      namespaces:
        symbol props Vehicle
        symbol props EthNM
        symbol props NM
    ErrorCode: compu {texttable}, range raw 0..1, type-emitter=TYPE_EMITTER_ARA, type-reference=uint32_t
      namespaces:
        symbol props Vehicle
        symbol props Vcc
        symbol props Policy
    ErrorInfo: compu {texttable}, range raw 0..3, type-emitter=TYPE_EMITTER_ARA, type-reference=uint32_t
      namespaces:
        symbol props Vehicle
        symbol props SOAAdaptor
        symbol props CANoverIP
    EthLinkStatus: compu {texttable}, range raw 0..2, type-emitter=TYPE_EMITTER_ARA, type-reference=uint32_t
      namespaces:
        symbol props Vehicle
        symbol props EthHandler
        symbol props EthernetSwitchMgr
    EthNetStatus: compu {texttable}, range raw 0..7, type-emitter=TYPE_EMITTER_ARA, type-reference=uint32_t
      namespaces:
        symbol props Vehicle
        symbol props ApSysMgr
        symbol props NetManager
    EthOtaError: compu {texttable}, range raw 0..10, type-emitter=TYPE_EMITTER_ARA, type-reference=uint32_t
      namespaces:
        symbol props Vehicle
        symbol props EthHandler
        symbol props EthernetSwitchMgr
    EthSwitchException: compu {texttable}, range raw 0..2, type-emitter=TYPE_EMITTER_ARA, type-reference=uint32_t
      namespaces:
        symbol props Vehicle
        symbol props EthHandler
        symbol props EthernetSwitchMgr
    EthSwitchStatus: compu {texttable}, range raw 0..5, type-emitter=TYPE_EMITTER_ARA, type-reference=uint32_t
      namespaces:
        symbol props Vehicle
        symbol props EthHandler
        symbol props EthernetSwitchMgr
    EthWireConnectionStatus: compu {texttable}, range raw 0..2, type-emitter=TYPE_EMITTER_ARA, type-reference=uint32_t
      namespaces:
        symbol props Vehicle
        symbol props EthHandler
        symbol props EthernetSwitchMgr
    EthernetError: compu {texttable}, range raw 0..4, type-emitter=TYPE_EMITTER_ARA, type-reference=uint32_t
      namespaces:
        symbol props Vehicle
        symbol props EthHandler
        symbol props EthernetSwitchMgr
    EventInfo: category=STRUCTURE, type-emitter=TYPE_EMITTER_ARA
      namespaces:
        symbol props BltnCam
        symbol props DrivingEvent
        symbol props Manager
      8 x cpp implementation data type element:
        eventID: type-reference={inplace=false, type-reference=String}  # Unique event identifier
        timeInfo: type-reference={inplace=false, type-reference=String}  # Time to save file and detect impact
        status: type-reference={inplace=false, type-reference=CPP/EventStatus}  # This provides the saved video status
        bltnCam_DEV_Count: type-reference={inplace=false, type-reference=uint32_t}  # Number of occurrences of events during driving
        gnss_Longitude: type-reference={inplace=false, type-reference=int32_t}
        gnss_Latitude: type-reference={inplace=false, type-reference=int32_t}
        mapmatchingType: type-reference={inplace=false, type-reference=CPP/MapmatchingType}
        files: type-reference={inplace=false, type-reference=CPP/EventInfo_files_VECTOR}
    EventInfo: category=STRUCTURE, type-emitter=TYPE_EMITTER_ARA
      namespaces:
        symbol props BltnCam
        symbol props ParkingEvent
        symbol props Manager
      8 x cpp implementation data type element:
        eventID: type-reference={inplace=false, type-reference=String}  # Unique event identifier
        timeInfo: type-reference={inplace=false, type-reference=String}  # Time to save file and detect impact
        status: type-reference={inplace=false, type-reference=CPP/EventStatus}  # This provides the saved video status
        bltnCam_PEV_Count: type-reference={inplace=false, type-reference=uint32_t}  # Number of occurrences of events during parking
        gnss_Longitude: type-reference={inplace=false, type-reference=int32_t}
        gnss_Latitude: type-reference={inplace=false, type-reference=int32_t}
        mapmatchingType: type-reference={inplace=false, type-reference=CPP/MapmatchingType}
        files: type-reference={inplace=false, type-reference=CPP/EventInfo_files_VECTOR}
    EventInfo_files_VECTOR: category=VECTOR, cpp-template-argument=CPP/FileInfo, type-emitter=TYPE_EMITTER_ARA
      namespaces:
        symbol props BltnCam
        symbol props DrivingEvent
        symbol props Manager
    EventInfo_files_VECTOR: category=VECTOR, cpp-template-argument=CPP/FileInfo, type-emitter=TYPE_EMITTER_ARA
      namespaces:
        symbol props BltnCam
        symbol props ParkingEvent
        symbol props Manager
    EventMcuLogData_EventData: category=STRUCTURE, type-emitter=TYPE_EMITTER_ARA
      namespaces:
        symbol props Vehicle
        symbol props IPCHandler
        symbol props RoutingIPC
      cpp implementation data type element mcuLog: type-reference={inplace=false, type-reference=String}
    EventNSDResetData_EventData: category=STRUCTURE, type-emitter=TYPE_EMITTER_ARA
      namespaces:
        symbol props Vehicle
        symbol props IPCHandler
        symbol props RoutingIPC
      cpp implementation data type element triggerReset: type-reference={inplace=false, type-reference=bool}
    EventNonSleepEcuIdx_EventData: category=STRUCTURE, type-emitter=TYPE_EMITTER_ARA
      namespaces:
        symbol props Vehicle
        symbol props IPCHandler
        symbol props RoutingIPC
      cpp implementation data type element nonSleepEcuIdx: type-reference={inplace=false, type-reference=NonSleepEcuIdx}
    EventPbsFirstWk_EventData: category=STRUCTURE, type-emitter=TYPE_EMITTER_ARA
      namespaces:
        symbol props Vehicle
        symbol props IPCHandler
        symbol props RoutingIPC
      cpp implementation data type element pbsFirstWakeup: type-reference={inplace=false, type-reference=uint8_t}
    EventStatus: compu {texttable}, range raw 0..3, type-emitter=TYPE_EMITTER_ARA, type-reference=uint32_t
      namespaces:
        symbol props BltnCam
        symbol props DrivingEvent
        symbol props Manager
    EventStatus: compu {texttable}, range raw 0..3, type-emitter=TYPE_EMITTER_ARA, type-reference=uint32_t
      namespaces:
        symbol props BltnCam
        symbol props ParkingEvent
        symbol props Manager
